VERSION ""

NS_ :

BS_:
BU_: MRR
BO_ 1073741824 VECTOR__INDEPENDENT_SIG_MSG: 0 Vector__XXX
   SG_ New_Signal_943 : 0|8@1+ (1,0) [0|0] "" Vector__XXX
   SG_ CAN_SENSOR_VANGLE_OFFSET : 0|8@0+ (0.0625,-8) [-8|7.9375] "deg" Vector__XXX
   SG_ CAN_SENSOR_FOV_VER : 0|8@0+ (1,0) [0|255] "deg" Vector__XXX
   SG_ CAN_AUTO_ALIGN_VANGLE_QF : 0|1@0+ (1,0) [0|1] "" Vector__XXX
   SG_ CAN_AUTO_ALIGN_VANGLE_REF : 0|10@0+ (0.03125,-10) [-10|21.9688] "deg" Vector__XXX
   SG_ CAN_AUTO_ALIGN_VANGLE : 0|10@0+ (0.03125,-10) [-10|21.9688] "deg" Vector__XXX
   SG_ CAN_MMIC_Temp4 : 0|8@0+ (1,-50) [-50|205] "C" Vector__XXX
   SG_ CAN_MMIC_Temp3 : 0|8@0+ (1,-50) [-50|205] "C" Vector__XXX
   SG_ CAN_MMIC_Temp2 : 0|8@0+ (1,-50) [-50|205] "C" Vector__XXX
   SG_ CAN_Processor_Temp2 : 0|8@0+ (1,-50) [-50|205] "C" Vector__XXX
   SG_ CAN_CHECKSUM : 0|8@0+ (1,0) [0|255] "" Vector__XXX
   SG_ CAN_COUNTER : 0|4@0+ (1,0) [0|15] "" Vector__XXX
   SG_ CAN_VEHICLE_MODE : 0|4@0+ (1,0) [0|15] "" Vector__XXX
   SG_ CAN_USC_CAL_VER_MAJOR : 0|16@0+ (1,0) [0|65535] "" Vector__XXX
   SG_ CAN_USC_CAL_VER_MINOR : 0|16@0+ (1,0) [0|65535] "" Vector__XXX
   SG_ CAN_SMC_CAL_VER_MAJOR : 0|16@0+ (1,0) [0|65535] "" Vector__XXX
   SG_ CAN_HW_VERSION : 0|32@0+ (1,0) [0|4.29497e+09] "" Vector__XXX
   SG_ CAN_FAC_TGT_MTG_SPACE_VER : 0|8@0+ (1,-128) [-128|127] "cm" Vector__XXX
   SG_ CAN_ANGLE_MISALIGNMENT_VER : 0|10@0+ (0.03125,-10) [-10|21.9688] "deg" Vector__XXX
   SG_ CAN_ANGLE_MOUNTING_VOFFSET : 0|8@0+ (0.0625,-8) [-8|7.9375] "deg" Vector__XXX
   SG_ CAN_LATCH_FAULTS : 0|64@0+ (1,0) [0|100] "" Vector__XXX
   SG_ CAN_ACTIVE_FAULTS : 0|64@0+ (1,0) [0|1.84467e+19] "" Vector__XXX
   SG_ CAN_HISTORY_FAULTS : 0|64@0+ (1,0) [0|1.84467e+19] "" Vector__XXX
   SG_ CAN_SERV_ALIGN_ENABLE : 0|1@0+ (1,0) [0|1] "" Vector__XXX
   SG_ CAN_LONG_MOUNTING_OFFSET : 0|8@0+ (0.015625,-2) [-2|1.98438] "" Vector__XXX
   SG_ CAN_BEAMWIDTH_VERT : 0|7@0+ (0.125,0) [0|15.875] "deg" Vector__XXX
   SG_ CAN_VEHICLE_SPEED_CALC_QF : 0|2@0+ (1,0) [0|3] "" Vector__XXX

BO_ 34 Active_Fault_Latched_2: 8 MRR
   SG_ IPMA_PCAN_DataRangeCheck : 4|1@1+ (1,0) [0|1] "" External_Tool
   SG_ IPMA_PCAN_MissingMsg : 3|1@1+ (1,0) [0|1] "" External_Tool
   SG_ VINSignalCompareFailure : 2|1@1+ (1,0) [0|1] "" External_Tool
   SG_ ModuleNotConfiguredError : 1|1@1+ (1,0) [0|1] "" External_Tool
   SG_ CarCfgNotConfiguredError : 0|1@1+ (1,0) [0|1] "" External_Tool

BO_ 33 Active_Fault_Latched_1: 8 MRR
   SG_ Active_Flt_Latched_byte7_bit7 : 63|1@1+ (1,0) [0|1] "" External_Tool
   SG_ Active_Flt_Latched_byte7_bit6 : 62|1@1+ (1,0) [0|1] "" External_Tool
   SG_ Active_Flt_Latched_byte7_bit5 : 61|1@1+ (1,0) [0|1] "" External_Tool
   SG_ Active_Flt_Latched_byte7_bit4 : 60|1@1+ (1,0) [0|1] "" External_Tool
   SG_ ARMtoDSPChksumFault : 59|1@1+ (1,0) [0|1] "" External_Tool
   SG_ DSPtoArmChksumFault : 58|1@1+ (1,0) [0|1] "" External_Tool
   SG_ HostToArmChksumFault : 57|1@1+ (1,0) [0|1] "" External_Tool
   SG_ ARMtoHostChksumFault : 56|1@1+ (1,0) [0|1] "" External_Tool
   SG_ LoopBWOutOfRange : 55|1@1+ (1,0) [0|1] "" External_Tool
   SG_ DSPOverrunFault : 54|1@1+ (1,0) [0|1] "" External_Tool
   SG_ Active_Flt_Latched_byte6_bit5 : 53|1@1+ (1,0) [0|1] "" External_Tool
   SG_ TuningSensitivityFault : 52|1@1+ (1,0) [0|1] "" External_Tool
   SG_ SaturatedTuningFreqFault : 51|1@1+ (1,0) [0|1] "" External_Tool
   SG_ LocalOscPowerFault : 50|1@1+ (1,0) [0|1] "" External_Tool
   SG_ TransmitterPowerFault : 49|1@1+ (1,0) [0|1] "" External_Tool
   SG_ Active_Flt_Latched_byte6_bit0 : 48|1@1+ (1,0) [0|1] "" External_Tool
   SG_ Active_Flt_Latched_byte5_bit7 : 47|1@1+ (1,0) [0|1] "" External_Tool
   SG_ Active_Flt_Latched_byte5_bit6 : 46|1@1+ (1,0) [0|1] "" External_Tool
   SG_ XCVRDeviceSPIFault : 45|1@1+ (1,0) [0|1] "" External_Tool
   SG_ FreqSynthesizerSPIFault : 44|1@1+ (1,0) [0|1] "" External_Tool
   SG_ AnalogConverterDevicSPIFault : 43|1@1+ (1,0) [0|1] "" External_Tool
   SG_ SidelobeBlockage : 42|1@1+ (1,0) [0|1] "" External_Tool
   SG_ Active_Flt_Latched_byte5_bit1 : 41|1@1+ (1,0) [0|1] "" External_Tool
   SG_ MNRBlocked : 40|1@1+ (1,0) [0|1] "" External_Tool
   SG_ ECUTempHighFault : 39|1@1+ (1,0) [0|1] "" External_Tool
   SG_ TransmitterTempHighFault : 38|1@1+ (1,0) [0|1] "" External_Tool
   SG_ AlignmentRoutineFailedFault : 37|1@1+ (1,0) [0|1] "" External_Tool
   SG_ UnreasonableRadarData : 36|1@1+ (1,0) [0|1] "" External_Tool
   SG_ MicroprocessorTempHighFault : 35|1@1+ (1,0) [0|1] "" External_Tool
   SG_ VerticalAlignmentOutOfRange : 34|1@1+ (1,0) [0|1] "" External_Tool
   SG_ HorizontalAlignmentOutOfRange : 33|1@1+ (1,0) [0|1] "" External_Tool
   SG_ FactoryAlignmentMode : 32|1@1+ (1,0) [0|1] "" External_Tool
   SG_ BatteryLowFault : 31|1@1+ (1,0) [0|1] "" External_Tool
   SG_ BatteryHighFault : 30|1@1+ (1,0) [0|1] "" External_Tool
   SG_ v_1p25SupplyOutOfRange : 29|1@1+ (1,0) [0|1] "" External_Tool
   SG_ Active_Flt_Latched_byte3_bit4 : 28|1@1+ (1,0) [0|1] "" External_Tool
   SG_ ThermistorOutOfRange : 27|1@1+ (1,0) [0|1] "" External_Tool
   SG_ v_3p3DACSupplyOutOfRange : 26|1@1+ (1,0) [0|1] "" External_Tool
   SG_ v_3p3RAWSupplyOutOfRange : 25|1@1+ (1,0) [0|1] "" External_Tool
   SG_ v_5_SupplyOutOfRange : 24|1@1+ (1,0) [0|1] "" External_Tool
   SG_ TransmitterIDFault : 23|1@1+ (1,0) [0|1] "" External_Tool
   SG_ Active_Flt_Latched_byte2_bit6 : 22|1@1+ (1,0) [0|1] "" External_Tool
   SG_ Active_Flt_Latched_byte2_bit5 : 21|1@1+ (1,0) [0|1] "" External_Tool
   SG_ Active_Flt_Latched_byte2_bit4 : 20|1@1+ (1,0) [0|1] "" External_Tool
   SG_ Active_Flt_Latched_byte2_bit3 : 19|1@1+ (1,0) [0|1] "" External_Tool
   SG_ Active_Flt_Latched_byte2_bit2 : 18|1@1+ (1,0) [0|1] "" External_Tool
   SG_ PCANMissingMsgFault : 17|1@1+ (1,0) [0|1] "" External_Tool
   SG_ PCANBusOff : 16|1@1+ (1,0) [0|1] "" External_Tool
   SG_ Active_Flt_Latched_byte1_bit7 : 15|1@1+ (1,0) [0|1] "" External_Tool
   SG_ Active_Flt_Latched_byte1_bit6 : 14|1@1+ (1,0) [0|1] "" External_Tool
   SG_ InstructionSetCheckFault : 13|1@1+ (1,0) [0|1] "" External_Tool
   SG_ StackOverflowFault : 12|1@1+ (1,0) [0|1] "" External_Tool
   SG_ WatchdogFault : 11|1@1+ (1,0) [0|1] "" External_Tool
   SG_ PLLLockFault : 10|1@1+ (1,0) [0|1] "" External_Tool
   SG_ Active_Flt_Latched_byte1_bit1 : 9|1@1+ (1,0) [0|1] "" External_Tool
   SG_ RAMMemoryTestFault : 8|1@1+ (1,0) [0|1] "" External_Tool
   SG_ USCValidationFault : 7|1@1+ (1,0) [0|1] "" External_Tool
   SG_ Active_Flt_Latched_byte0_bit6 : 6|1@1+ (1,0) [0|1] "" External_Tool
   SG_ Active_Flt_Latched_byte0_bit5 : 5|1@1+ (1,0) [0|1] "" External_Tool
   SG_ Active_Flt_Latched_byte0_bit4 : 4|1@1+ (1,0) [0|1] "" External_Tool
   SG_ Active_Flt_Latched_byte0_bit3 : 3|1@1+ (1,0) [0|1] "" External_Tool
   SG_ KeepAliveChecksumFault : 2|1@1+ (1,0) [0|1] "" External_Tool
   SG_ ProgramCalibrationFlashChecksum : 1|1@1+ (1,0) [0|1] "" External_Tool
   SG_ ApplicationFlashChecksumFault : 0|1@1+ (1,0) [0|1] "" External_Tool

BO_ 500 XCP_MRR_DAQ_RESP: 8 MRR
   SG_ MRR_xcp_daq_resp_byte7 : 63|8@0+ (1,0) [0|255] "" External_Tool
   SG_ MRR_xcp_daq_resp_byte6 : 55|8@0+ (1,0) [0|255] "" External_Tool
   SG_ MRR_xcp_daq_resp_byte5 : 47|8@0+ (1,0) [0|255] "" External_Tool
   SG_ MRR_xcp_daq_resp_byte4 : 39|8@0+ (1,0) [0|255] "" External_Tool
   SG_ MRR_xcp_daq_resp_byte3 : 31|8@0+ (1,0) [0|255] "" External_Tool
   SG_ MRR_xcp_daq_resp_byte2 : 23|8@0+ (1,0) [0|255] "" External_Tool
   SG_ MRR_xcp_daq_resp_byte1 : 15|8@0+ (1,0) [0|255] "" External_Tool
   SG_ MRR_xcp_daq_resp_byte0 : 7|8@0+ (1,0) [0|255] "" External_Tool

BO_ 499 XCP_MRR_DTO_RESP: 8 MRR
   SG_ MRR_xcp_dto_resp_byte7 : 63|8@0+ (1,0) [0|255] "" External_Tool
   SG_ MRR_xcp_dto_resp_byte6 : 55|8@0+ (1,0) [0|255] "" External_Tool
   SG_ MRR_xcp_dto_resp_byte5 : 47|8@0+ (1,0) [0|255] "" External_Tool
   SG_ MRR_xcp_dto_resp_byte4 : 39|8@0+ (1,0) [0|255] "" External_Tool
   SG_ MRR_xcp_dto_resp_byte3 : 31|8@0+ (1,0) [0|255] "" External_Tool
   SG_ MRR_xcp_dto_resp_byte2 : 23|8@0+ (1,0) [0|255] "" External_Tool
   SG_ MRR_xcp_dto_resp_byte1 : 15|8@0+ (1,0) [0|255] "" External_Tool
   SG_ MRR_xcp_dto_resp_byte0 : 7|8@0+ (1,0) [0|255] "" External_Tool

BO_ 497 XCP_MRR_CTO_RESP: 8 MRR
   SG_ MRR_xcp_cto_resp_byte7 : 63|8@0+ (1,0) [0|255] "" External_Tool
   SG_ MRR_xcp_cto_resp_byte6 : 55|8@0+ (1,0) [0|255] "" External_Tool
   SG_ MRR_xcp_cto_resp_byte5 : 47|8@0+ (1,0) [0|255] "" External_Tool
   SG_ MRR_xcp_cto_resp_byte4 : 39|8@0+ (1,0) [0|255] "" External_Tool
   SG_ MRR_xcp_cto_resp_byte3 : 31|8@0+ (1,0) [0|255] "" External_Tool
   SG_ MRR_xcp_cto_resp_byte2 : 23|8@0+ (1,0) [0|255] "" External_Tool
   SG_ MRR_xcp_cto_resp_byte1 : 15|8@0+ (1,0) [0|255] "" External_Tool
   SG_ MRR_xcp_cto_resp_byte0 : 7|8@0+ (1,0) [0|255] "" External_Tool

BO_ 1900 Ford_Diag_Resp_Phys: 8 MRR
   SG_ TesterPhysicalResCCM : 7|64@0+ (1,0) [0|1.84467e+19] "" IFV_Host

BO_ 261 MRR_Status_SerialNumber: 8 MRR
   SG_ CAN_SEQUENCE_NUMBER : 55|16@0+ (1,0) [0|65535] "" External_Tool
   SG_ CAN_SERIAL_NUMBER : 7|40@0+ (1,0) [0|1.09951e+12] "" External_Tool

BO_ 264 MRR_Status_SwVersion: 8 MRR
   SG_ CAN_PBL_Field_Revision : 47|8@0+ (1,0) [0|255] "" External_Tool
   SG_ CAN_PBL_Promote_Revision : 39|8@0+ (1,0) [0|255] "" External_Tool
   SG_ CAN_SW_Field_Revision : 23|8@0+ (1,0) [0|255] "" External_Tool
   SG_ CAN_SW_Promote_Revision : 15|8@0+ (1,0) [0|255] "" External_Tool
   SG_ CAN_SW_Release_Revision : 7|8@0+ (1,0) [0|255] "" External_Tool
   SG_ CAN_PBL_Release_Revision : 31|8@0+ (1,0) [0|255] "" External_Tool

BO_ 373 MRR_Header_SensorPosition: 8 MRR
   SG_ CAN_SENSOR_POLARITY : 55|1@0+ (1,0) [0|1] "" External_Tool
   SG_ CAN_SENSOR_LAT_OFFSET : 39|16@0+ (0.01,0) [0|655.35] "cm" External_Tool
   SG_ CAN_SENSOR_LONG_OFFSET : 23|16@0+ (0.01,0) [0|655.35] "cm" External_Tool
   SG_ CAN_SENSOR_HANGLE_OFFSET : 7|8@0+ (0.0625,-8) [-8|7.9375] "deg" External_Tool

BO_ 372 MRR_Header_SensorCoverage: 8 MRR
   SG_ CAN_SENSOR_FOV_HOR : 39|8@0+ (1,0) [0|255] "deg" IFV_VFP
   SG_ CAN_DOPPLER_COVERAGE : 23|8@0+ (1,-128) [-128|127] "m/s" IFV_VFP
   SG_ CAN_RANGE_COVERAGE : 7|8@0+ (1,0) [0|255] "m" IFV_VFP

BO_ 371 MRR_Header_AlignmentState: 8 MRR
   SG_ CAN_AUTO_ALIGN_HANGLE_QF : 13|2@0+ (1,0) [0|3] "" IFV_VFP
   SG_ CAN_ALIGNMENT_STATUS : 51|4@0+ (1,0) [0|11] "" IFV_VFP
   SG_ CAN_ALIGNMENT_STATE : 55|3@0+ (1,0) [0|7] "" IFV_VFP
   SG_ CAN_AUTO_ALIGN_HANGLE_REF : 11|10@0+ (0.000341218,-0.174533) [-0.174533|0.174533] "rad" IFV_VFP
   SG_ CAN_AUTO_ALIGN_HANGLE : 7|10@0+ (0.000341218,-0.174533) [-0.174533|0.174533] "rad" IFV_VFP

BO_ 369 MRR_Header_Timestamps: 8 MRR
   SG_ CAN_DET_TIME_SINCE_MEAS : 39|11@0+ (0.1,0) [0|204.7] "ms" IFV_Host
   SG_ CAN_SENSOR_TIME_STAMP : 7|32@0+ (0.1,0) [0|4.29497e+08] "ms" IFV_VFP

BO_ 368 MRR_Header_InformationDetections: 8 MRR
   SG_ CAN_ALIGN_UPDATES_DONE : 55|16@0+ (1,0) [0|65535] "" IFV_VFP
   SG_ CAN_SCAN_INDEX : 31|16@0+ (1,0) [0|65535] "" IFV_VFP
   SG_ CAN_NUMBER_OF_DET : 47|8@0+ (1,0) [0|255] "" External_Tool
   SG_ CAN_LOOK_ID : 23|2@0+ (1,0) [0|3] "" External_Tool
   SG_ CAN_LOOK_INDEX : 7|16@0+ (1,0) [0|65535] "" External_Tool

BO_ 265 MRR_Status_Temp_Volt: 8 MRR
   SG_ CAN_BATT_VOLTS : 63|8@0+ (0.08,0) [0|20.4] "V" External_Tool
   SG_ CAN_1_25_V : 55|8@0+ (0.08,0) [0|20.4] "V" External_Tool
   SG_ CAN_5_V : 47|8@0+ (0.08,0) [0|20.4] "V" External_Tool
   SG_ CAN_3_3_V_RAW : 31|8@0+ (0.08,0) [0|20.4] "V" External_Tool
   SG_ CAN_3_3_V_DAC : 15|8@0+ (0.08,0) [0|20.4] "V" External_Tool
   SG_ CAN_MMIC_Temp1 : 39|8@0+ (1,-50) [-50|205] "C" External_Tool
   SG_ CAN_Processor_Thermistor : 23|8@0+ (1,-50) [-50|205] "C" External_Tool
   SG_ CAN_Processor_Temp1 : 7|8@0+ (1,-50) [-50|205] "C" External_Tool

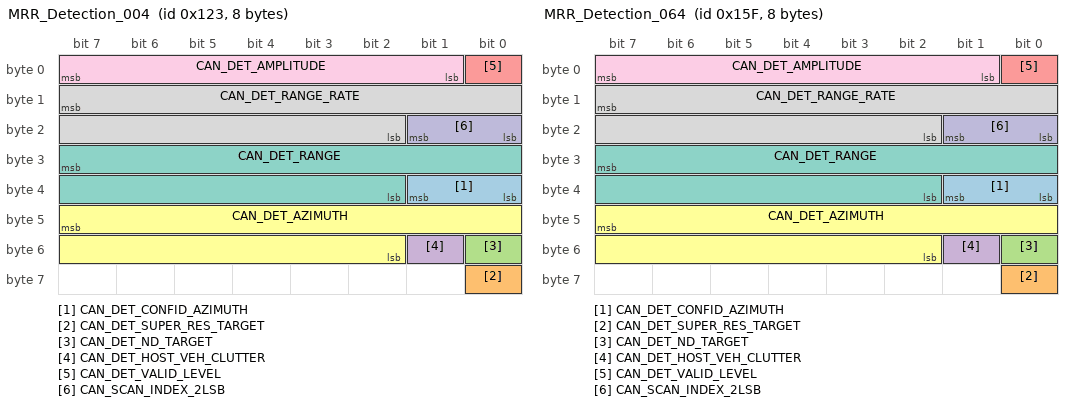
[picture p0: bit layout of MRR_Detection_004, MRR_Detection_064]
BO_ 291 MRR_Detection_004: 8 MRR
   SG_ CAN_DET_CONFID_AZIMUTH : 33|2@0+ (1,0) [0|3] "" IFV_VFP
   SG_ CAN_DET_SUPER_RES_TARGET : 56|1@0+ (1,0) [0|1] "" IFV_VFP
   SG_ CAN_DET_ND_TARGET : 48|1@0+ (1,0) [0|1] "" IFV_VFP
   SG_ CAN_DET_HOST_VEH_CLUTTER : 49|1@0+ (1,0) [0|1] "" IFV_VFP
   SG_ CAN_DET_VALID_LEVEL : 0|1@0+ (1,0) [0|1] "" IFV_VFP
   SG_ CAN_DET_AZIMUTH : 47|14@0+ (0.0003834,-3.1416) [-3.1416|3.13964] "rad" IFV_VFP
   SG_ CAN_DET_RANGE : 31|14@0+ (0.015625,0) [0|255.984] "m" IFV_VFP
   SG_ CAN_DET_RANGE_RATE : 15|14@0+ (0.015625,-128) [-128|127.984] "m/s" IFV_VFP
   SG_ CAN_DET_AMPLITUDE : 7|7@0+ (1,-64) [-64|63] "dBsm" IFV_VFP
   SG_ CAN_SCAN_INDEX_2LSB : 17|2@0+ (1,0) [0|3] "" IFV_VFP

BO_ 351 MRR_Detection_064: 8 MRR
  SG_ CAN_DET_CONFID_AZIMUTH : 33|2@0+ (1,0) [0|3] "" IFV_VFP
  SG_ CAN_DET_SUPER_RES_TARGET : 56|1@0+ (1,0) [0|1] "" IFV_VFP
  SG_ CAN_DET_ND_TARGET : 48|1@0+ (1,0) [0|1] "" IFV_VFP
  SG_ CAN_DET_HOST_VEH_CLUTTER : 49|1@0+ (1,0) [0|1] "" IFV_VFP
  SG_ CAN_DET_VALID_LEVEL : 0|1@0+ (1,0) [0|1] "" IFV_VFP
  SG_ CAN_DET_AZIMUTH : 47|14@0+ (0.0003834,-3.1416) [-3.1416|3.13964] "rad" IFV_VFP
  SG_ CAN_DET_RANGE : 31|14@0+ (0.015625,0) [0|255.984] "m" IFV_VFP
  SG_ CAN_DET_RANGE_RATE : 15|14@0+ (0.015625,-128) [-128|127.984] "m/s" IFV_VFP
  SG_ CAN_DET_AMPLITUDE : 7|7@0+ (1,-64) [-64|63] "dBsm" IFV_VFP
  SG_ CAN_SCAN_INDEX_2LSB : 17|2@0+ (1,0) [0|3] "" IFV_VFP

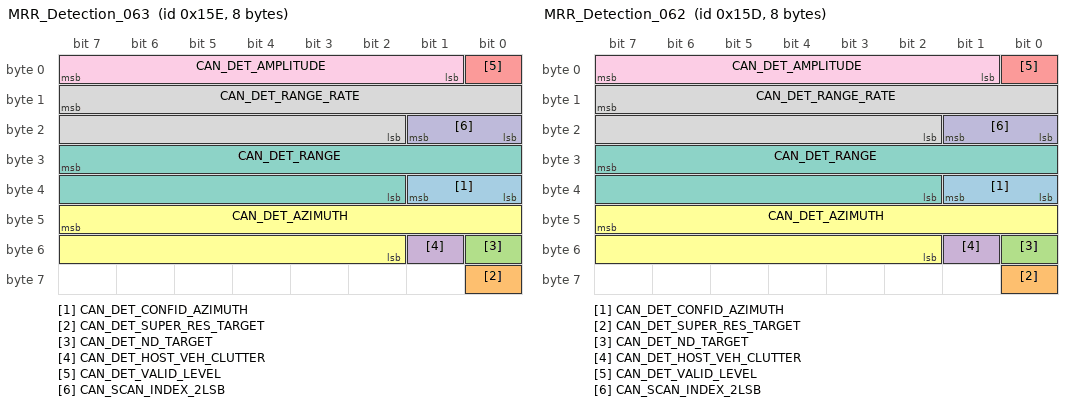
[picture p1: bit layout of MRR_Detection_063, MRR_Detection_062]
BO_ 350 MRR_Detection_063: 8 MRR
  SG_ CAN_DET_CONFID_AZIMUTH : 33|2@0+ (1,0) [0|3] "" IFV_VFP
  SG_ CAN_DET_SUPER_RES_TARGET : 56|1@0+ (1,0) [0|1] "" IFV_VFP
  SG_ CAN_DET_ND_TARGET : 48|1@0+ (1,0) [0|1] "" IFV_VFP
  SG_ CAN_DET_HOST_VEH_CLUTTER : 49|1@0+ (1,0) [0|1] "" IFV_VFP
  SG_ CAN_DET_VALID_LEVEL : 0|1@0+ (1,0) [0|1] "" IFV_VFP
  SG_ CAN_DET_AZIMUTH : 47|14@0+ (0.0003834,-3.1416) [-3.1416|3.13964] "rad" IFV_VFP
  SG_ CAN_DET_RANGE : 31|14@0+ (0.015625,0) [0|255.984] "m" IFV_VFP
  SG_ CAN_DET_RANGE_RATE : 15|14@0+ (0.015625,-128) [-128|127.984] "m/s" IFV_VFP
  SG_ CAN_DET_AMPLITUDE : 7|7@0+ (1,-64) [-64|63] "dBsm" IFV_VFP
  SG_ CAN_SCAN_INDEX_2LSB : 17|2@0+ (1,0) [0|3] "" IFV_VFP

BO_ 349 MRR_Detection_062: 8 MRR
  SG_ CAN_DET_CONFID_AZIMUTH : 33|2@0+ (1,0) [0|3] "" IFV_VFP
  SG_ CAN_DET_SUPER_RES_TARGET : 56|1@0+ (1,0) [0|1] "" IFV_VFP
  SG_ CAN_DET_ND_TARGET : 48|1@0+ (1,0) [0|1] "" IFV_VFP
  SG_ CAN_DET_HOST_VEH_CLUTTER : 49|1@0+ (1,0) [0|1] "" IFV_VFP
  SG_ CAN_DET_VALID_LEVEL : 0|1@0+ (1,0) [0|1] "" IFV_VFP
  SG_ CAN_DET_AZIMUTH : 47|14@0+ (0.0003834,-3.1416) [-3.1416|3.13964] "rad" IFV_VFP
  SG_ CAN_DET_RANGE : 31|14@0+ (0.015625,0) [0|255.984] "m" IFV_VFP
  SG_ CAN_DET_RANGE_RATE : 15|14@0+ (0.015625,-128) [-128|127.984] "m/s" IFV_VFP
  SG_ CAN_DET_AMPLITUDE : 7|7@0+ (1,-64) [-64|63] "dBsm" IFV_VFP
  SG_ CAN_SCAN_INDEX_2LSB : 17|2@0+ (1,0) [0|3] "" IFV_VFP

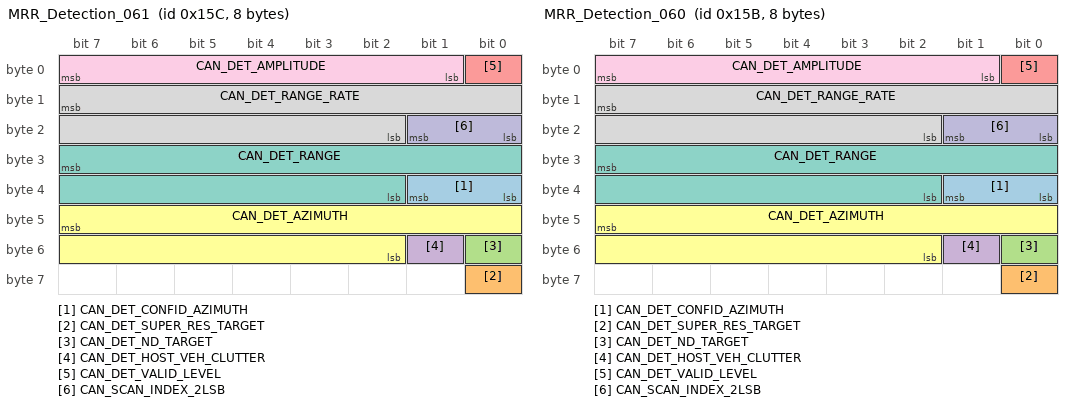
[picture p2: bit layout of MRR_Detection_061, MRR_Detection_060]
BO_ 348 MRR_Detection_061: 8 MRR
  SG_ CAN_DET_CONFID_AZIMUTH : 33|2@0+ (1,0) [0|3] "" IFV_VFP
  SG_ CAN_DET_SUPER_RES_TARGET : 56|1@0+ (1,0) [0|1] "" IFV_VFP
  SG_ CAN_DET_ND_TARGET : 48|1@0+ (1,0) [0|1] "" IFV_VFP
  SG_ CAN_DET_HOST_VEH_CLUTTER : 49|1@0+ (1,0) [0|1] "" IFV_VFP
  SG_ CAN_DET_VALID_LEVEL : 0|1@0+ (1,0) [0|1] "" IFV_VFP
  SG_ CAN_DET_AZIMUTH : 47|14@0+ (0.0003834,-3.1416) [-3.1416|3.13964] "rad" IFV_VFP
  SG_ CAN_DET_RANGE : 31|14@0+ (0.015625,0) [0|255.984] "m" IFV_VFP
  SG_ CAN_DET_RANGE_RATE : 15|14@0+ (0.015625,-128) [-128|127.984] "m/s" IFV_VFP
  SG_ CAN_DET_AMPLITUDE : 7|7@0+ (1,-64) [-64|63] "dBsm" IFV_VFP
  SG_ CAN_SCAN_INDEX_2LSB : 17|2@0+ (1,0) [0|3] "" IFV_VFP

BO_ 347 MRR_Detection_060: 8 MRR
  SG_ CAN_DET_CONFID_AZIMUTH : 33|2@0+ (1,0) [0|3] "" IFV_VFP
  SG_ CAN_DET_SUPER_RES_TARGET : 56|1@0+ (1,0) [0|1] "" IFV_VFP
  SG_ CAN_DET_ND_TARGET : 48|1@0+ (1,0) [0|1] "" IFV_VFP
  SG_ CAN_DET_HOST_VEH_CLUTTER : 49|1@0+ (1,0) [0|1] "" IFV_VFP
  SG_ CAN_DET_VALID_LEVEL : 0|1@0+ (1,0) [0|1] "" IFV_VFP
  SG_ CAN_DET_AZIMUTH : 47|14@0+ (0.0003834,-3.1416) [-3.1416|3.13964] "rad" IFV_VFP
  SG_ CAN_DET_RANGE : 31|14@0+ (0.015625,0) [0|255.984] "m" IFV_VFP
  SG_ CAN_DET_RANGE_RATE : 15|14@0+ (0.015625,-128) [-128|127.984] "m/s" IFV_VFP
  SG_ CAN_DET_AMPLITUDE : 7|7@0+ (1,-64) [-64|63] "dBsm" IFV_VFP
  SG_ CAN_SCAN_INDEX_2LSB : 17|2@0+ (1,0) [0|3] "" IFV_VFP

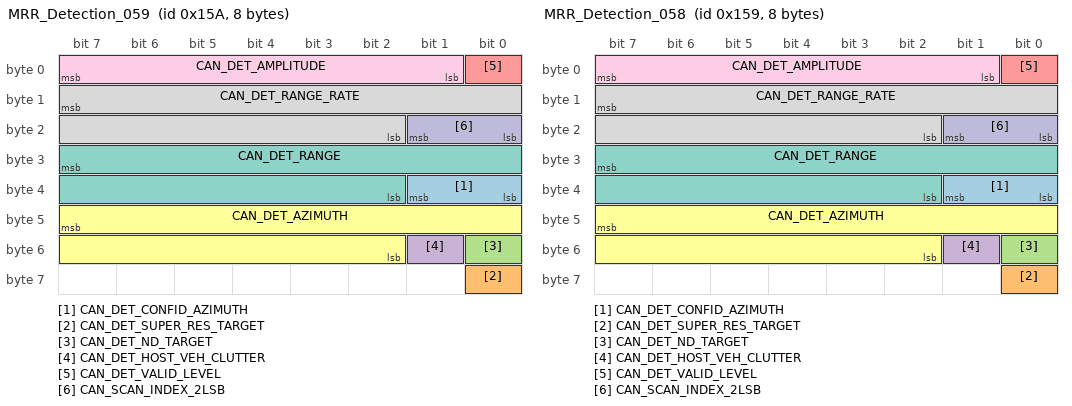
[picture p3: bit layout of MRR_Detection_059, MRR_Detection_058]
BO_ 346 MRR_Detection_059: 8 MRR
  SG_ CAN_DET_CONFID_AZIMUTH : 33|2@0+ (1,0) [0|3] "" IFV_VFP
  SG_ CAN_DET_SUPER_RES_TARGET : 56|1@0+ (1,0) [0|1] "" IFV_VFP
  SG_ CAN_DET_ND_TARGET : 48|1@0+ (1,0) [0|1] "" IFV_VFP
  SG_ CAN_DET_HOST_VEH_CLUTTER : 49|1@0+ (1,0) [0|1] "" IFV_VFP
  SG_ CAN_DET_VALID_LEVEL : 0|1@0+ (1,0) [0|1] "" IFV_VFP
  SG_ CAN_DET_AZIMUTH : 47|14@0+ (0.0003834,-3.1416) [-3.1416|3.13964] "rad" IFV_VFP
  SG_ CAN_DET_RANGE : 31|14@0+ (0.015625,0) [0|255.984] "m" IFV_VFP
  SG_ CAN_DET_RANGE_RATE : 15|14@0+ (0.015625,-128) [-128|127.984] "m/s" IFV_VFP
  SG_ CAN_DET_AMPLITUDE : 7|7@0+ (1,-64) [-64|63] "dBsm" IFV_VFP
  SG_ CAN_SCAN_INDEX_2LSB : 17|2@0+ (1,0) [0|3] "" IFV_VFP

BO_ 345 MRR_Detection_058: 8 MRR
  SG_ CAN_DET_CONFID_AZIMUTH : 33|2@0+ (1,0) [0|3] "" IFV_VFP
  SG_ CAN_DET_SUPER_RES_TARGET : 56|1@0+ (1,0) [0|1] "" IFV_VFP
  SG_ CAN_DET_ND_TARGET : 48|1@0+ (1,0) [0|1] "" IFV_VFP
  SG_ CAN_DET_HOST_VEH_CLUTTER : 49|1@0+ (1,0) [0|1] "" IFV_VFP
  SG_ CAN_DET_VALID_LEVEL : 0|1@0+ (1,0) [0|1] "" IFV_VFP
  SG_ CAN_DET_AZIMUTH : 47|14@0+ (0.0003834,-3.1416) [-3.1416|3.13964] "rad" IFV_VFP
  SG_ CAN_DET_RANGE : 31|14@0+ (0.015625,0) [0|255.984] "m" IFV_VFP
  SG_ CAN_DET_RANGE_RATE : 15|14@0+ (0.015625,-128) [-128|127.984] "m/s" IFV_VFP
  SG_ CAN_DET_AMPLITUDE : 7|7@0+ (1,-64) [-64|63] "dBsm" IFV_VFP
  SG_ CAN_SCAN_INDEX_2LSB : 17|2@0+ (1,0) [0|3] "" IFV_VFP

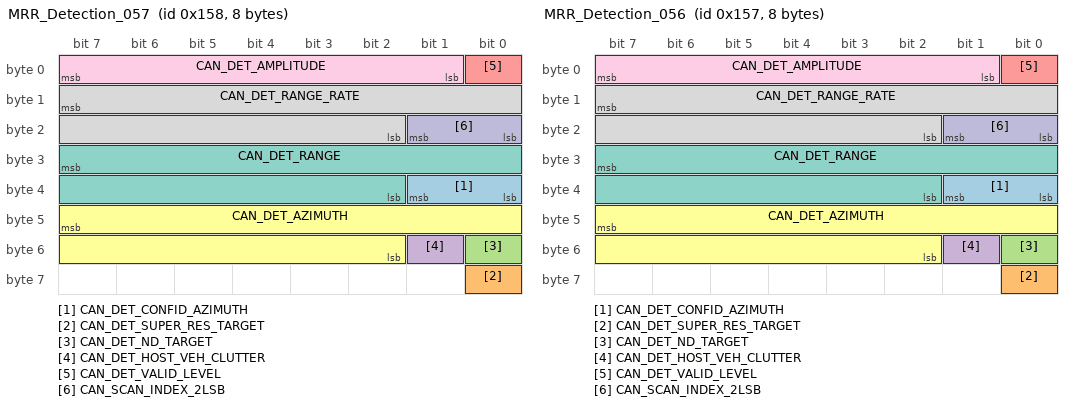
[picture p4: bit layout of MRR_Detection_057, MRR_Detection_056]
BO_ 344 MRR_Detection_057: 8 MRR
  SG_ CAN_DET_CONFID_AZIMUTH : 33|2@0+ (1,0) [0|3] "" IFV_VFP
  SG_ CAN_DET_SUPER_RES_TARGET : 56|1@0+ (1,0) [0|1] "" IFV_VFP
  SG_ CAN_DET_ND_TARGET : 48|1@0+ (1,0) [0|1] "" IFV_VFP
  SG_ CAN_DET_HOST_VEH_CLUTTER : 49|1@0+ (1,0) [0|1] "" IFV_VFP
  SG_ CAN_DET_VALID_LEVEL : 0|1@0+ (1,0) [0|1] "" IFV_VFP
  SG_ CAN_DET_AZIMUTH : 47|14@0+ (0.0003834,-3.1416) [-3.1416|3.13964] "rad" IFV_VFP
  SG_ CAN_DET_RANGE : 31|14@0+ (0.015625,0) [0|255.984] "m" IFV_VFP
  SG_ CAN_DET_RANGE_RATE : 15|14@0+ (0.015625,-128) [-128|127.984] "m/s" IFV_VFP
  SG_ CAN_DET_AMPLITUDE : 7|7@0+ (1,-64) [-64|63] "dBsm" IFV_VFP
  SG_ CAN_SCAN_INDEX_2LSB : 17|2@0+ (1,0) [0|3] "" IFV_VFP

BO_ 343 MRR_Detection_056: 8 MRR
  SG_ CAN_DET_CONFID_AZIMUTH : 33|2@0+ (1,0) [0|3] "" IFV_VFP
  SG_ CAN_DET_SUPER_RES_TARGET : 56|1@0+ (1,0) [0|1] "" IFV_VFP
  SG_ CAN_DET_ND_TARGET : 48|1@0+ (1,0) [0|1] "" IFV_VFP
  SG_ CAN_DET_HOST_VEH_CLUTTER : 49|1@0+ (1,0) [0|1] "" IFV_VFP
  SG_ CAN_DET_VALID_LEVEL : 0|1@0+ (1,0) [0|1] "" IFV_VFP
  SG_ CAN_DET_AZIMUTH : 47|14@0+ (0.0003834,-3.1416) [-3.1416|3.13964] "rad" IFV_VFP
  SG_ CAN_DET_RANGE : 31|14@0+ (0.015625,0) [0|255.984] "m" IFV_VFP
  SG_ CAN_DET_RANGE_RATE : 15|14@0+ (0.015625,-128) [-128|127.984] "m/s" IFV_VFP
  SG_ CAN_DET_AMPLITUDE : 7|7@0+ (1,-64) [-64|63] "dBsm" IFV_VFP
  SG_ CAN_SCAN_INDEX_2LSB : 17|2@0+ (1,0) [0|3] "" IFV_VFP

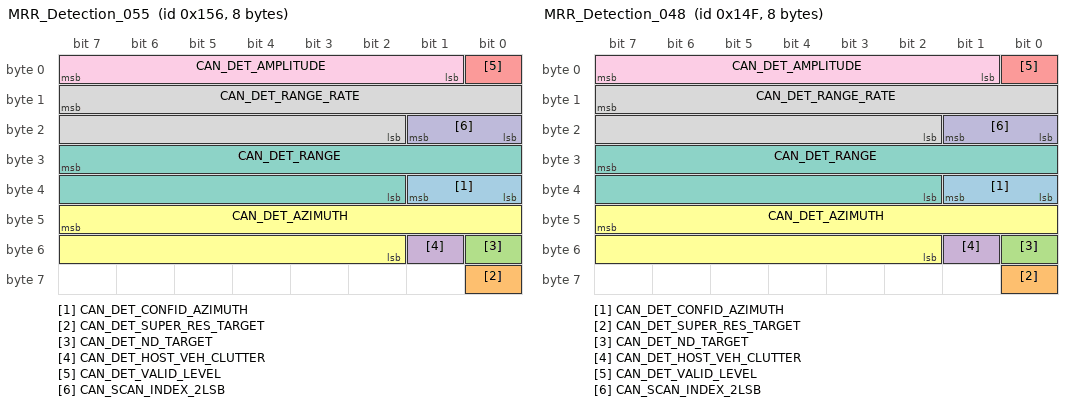
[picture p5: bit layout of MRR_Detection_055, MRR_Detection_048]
BO_ 342 MRR_Detection_055: 8 MRR
  SG_ CAN_DET_CONFID_AZIMUTH : 33|2@0+ (1,0) [0|3] "" IFV_VFP
  SG_ CAN_DET_SUPER_RES_TARGET : 56|1@0+ (1,0) [0|1] "" IFV_VFP
  SG_ CAN_DET_ND_TARGET : 48|1@0+ (1,0) [0|1] "" IFV_VFP
  SG_ CAN_DET_HOST_VEH_CLUTTER : 49|1@0+ (1,0) [0|1] "" IFV_VFP
  SG_ CAN_DET_VALID_LEVEL : 0|1@0+ (1,0) [0|1] "" IFV_VFP
  SG_ CAN_DET_AZIMUTH : 47|14@0+ (0.0003834,-3.1416) [-3.1416|3.13964] "rad" IFV_VFP
  SG_ CAN_DET_RANGE : 31|14@0+ (0.015625,0) [0|255.984] "m" IFV_VFP
  SG_ CAN_DET_RANGE_RATE : 15|14@0+ (0.015625,-128) [-128|127.984] "m/s" IFV_VFP
  SG_ CAN_DET_AMPLITUDE : 7|7@0+ (1,-64) [-64|63] "dBsm" IFV_VFP
  SG_ CAN_SCAN_INDEX_2LSB : 17|2@0+ (1,0) [0|3] "" IFV_VFP

BO_ 335 MRR_Detection_048: 8 MRR
  SG_ CAN_DET_CONFID_AZIMUTH : 33|2@0+ (1,0) [0|3] "" IFV_VFP
  SG_ CAN_DET_SUPER_RES_TARGET : 56|1@0+ (1,0) [0|1] "" IFV_VFP
  SG_ CAN_DET_ND_TARGET : 48|1@0+ (1,0) [0|1] "" IFV_VFP
  SG_ CAN_DET_HOST_VEH_CLUTTER : 49|1@0+ (1,0) [0|1] "" IFV_VFP
  SG_ CAN_DET_VALID_LEVEL : 0|1@0+ (1,0) [0|1] "" IFV_VFP
  SG_ CAN_DET_AZIMUTH : 47|14@0+ (0.0003834,-3.1416) [-3.1416|3.13964] "rad" IFV_VFP
  SG_ CAN_DET_RANGE : 31|14@0+ (0.015625,0) [0|255.984] "m" IFV_VFP
  SG_ CAN_DET_RANGE_RATE : 15|14@0+ (0.015625,-128) [-128|127.984] "m/s" IFV_VFP
  SG_ CAN_DET_AMPLITUDE : 7|7@0+ (1,-64) [-64|63] "dBsm" IFV_VFP
  SG_ CAN_SCAN_INDEX_2LSB : 17|2@0+ (1,0) [0|3] "" IFV_VFP

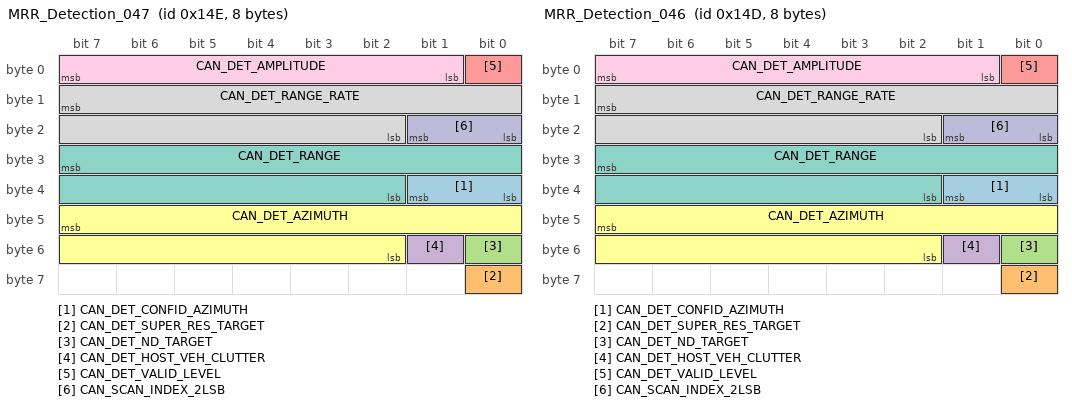
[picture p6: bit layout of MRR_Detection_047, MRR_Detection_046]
BO_ 334 MRR_Detection_047: 8 MRR
  SG_ CAN_DET_CONFID_AZIMUTH : 33|2@0+ (1,0) [0|3] "" IFV_VFP
  SG_ CAN_DET_SUPER_RES_TARGET : 56|1@0+ (1,0) [0|1] "" IFV_VFP
  SG_ CAN_DET_ND_TARGET : 48|1@0+ (1,0) [0|1] "" IFV_VFP
  SG_ CAN_DET_HOST_VEH_CLUTTER : 49|1@0+ (1,0) [0|1] "" IFV_VFP
  SG_ CAN_DET_VALID_LEVEL : 0|1@0+ (1,0) [0|1] "" IFV_VFP
  SG_ CAN_DET_AZIMUTH : 47|14@0+ (0.0003834,-3.1416) [-3.1416|3.13964] "rad" IFV_VFP
  SG_ CAN_DET_RANGE : 31|14@0+ (0.015625,0) [0|255.984] "m" IFV_VFP
  SG_ CAN_DET_RANGE_RATE : 15|14@0+ (0.015625,-128) [-128|127.984] "m/s" IFV_VFP
  SG_ CAN_DET_AMPLITUDE : 7|7@0+ (1,-64) [-64|63] "dBsm" IFV_VFP
  SG_ CAN_SCAN_INDEX_2LSB : 17|2@0+ (1,0) [0|3] "" IFV_VFP

BO_ 333 MRR_Detection_046: 8 MRR
  SG_ CAN_DET_CONFID_AZIMUTH : 33|2@0+ (1,0) [0|3] "" IFV_VFP
  SG_ CAN_DET_SUPER_RES_TARGET : 56|1@0+ (1,0) [0|1] "" IFV_VFP
  SG_ CAN_DET_ND_TARGET : 48|1@0+ (1,0) [0|1] "" IFV_VFP
  SG_ CAN_DET_HOST_VEH_CLUTTER : 49|1@0+ (1,0) [0|1] "" IFV_VFP
  SG_ CAN_DET_VALID_LEVEL : 0|1@0+ (1,0) [0|1] "" IFV_VFP
  SG_ CAN_DET_AZIMUTH : 47|14@0+ (0.0003834,-3.1416) [-3.1416|3.13964] "rad" IFV_VFP
  SG_ CAN_DET_RANGE : 31|14@0+ (0.015625,0) [0|255.984] "m" IFV_VFP
  SG_ CAN_DET_RANGE_RATE : 15|14@0+ (0.015625,-128) [-128|127.984] "m/s" IFV_VFP
  SG_ CAN_DET_AMPLITUDE : 7|7@0+ (1,-64) [-64|63] "dBsm" IFV_VFP
  SG_ CAN_SCAN_INDEX_2LSB : 17|2@0+ (1,0) [0|3] "" IFV_VFP

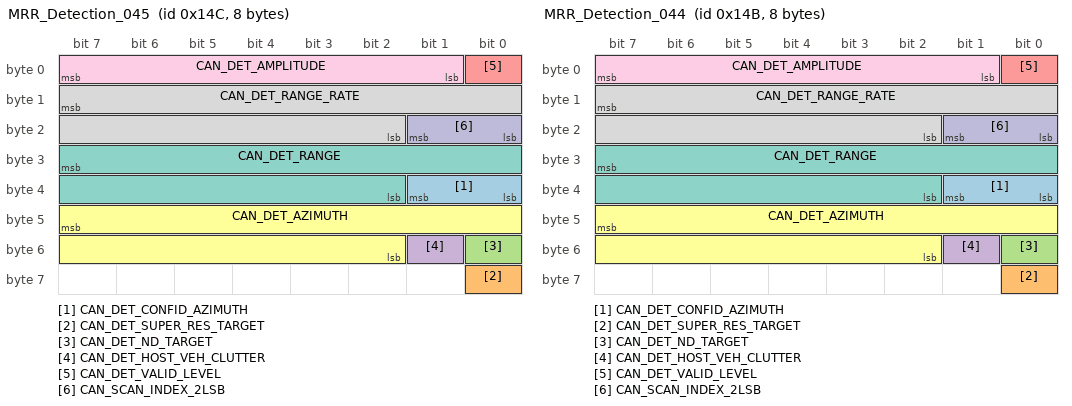
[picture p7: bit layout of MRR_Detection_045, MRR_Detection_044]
BO_ 332 MRR_Detection_045: 8 MRR
  SG_ CAN_DET_CONFID_AZIMUTH : 33|2@0+ (1,0) [0|3] "" IFV_VFP
  SG_ CAN_DET_SUPER_RES_TARGET : 56|1@0+ (1,0) [0|1] "" IFV_VFP
  SG_ CAN_DET_ND_TARGET : 48|1@0+ (1,0) [0|1] "" IFV_VFP
  SG_ CAN_DET_HOST_VEH_CLUTTER : 49|1@0+ (1,0) [0|1] "" IFV_VFP
  SG_ CAN_DET_VALID_LEVEL : 0|1@0+ (1,0) [0|1] "" IFV_VFP
  SG_ CAN_DET_AZIMUTH : 47|14@0+ (0.0003834,-3.1416) [-3.1416|3.13964] "rad" IFV_VFP
  SG_ CAN_DET_RANGE : 31|14@0+ (0.015625,0) [0|255.984] "m" IFV_VFP
  SG_ CAN_DET_RANGE_RATE : 15|14@0+ (0.015625,-128) [-128|127.984] "m/s" IFV_VFP
  SG_ CAN_DET_AMPLITUDE : 7|7@0+ (1,-64) [-64|63] "dBsm" IFV_VFP
  SG_ CAN_SCAN_INDEX_2LSB : 17|2@0+ (1,0) [0|3] "" IFV_VFP

BO_ 331 MRR_Detection_044: 8 MRR
  SG_ CAN_DET_CONFID_AZIMUTH : 33|2@0+ (1,0) [0|3] "" IFV_VFP
  SG_ CAN_DET_SUPER_RES_TARGET : 56|1@0+ (1,0) [0|1] "" IFV_VFP
  SG_ CAN_DET_ND_TARGET : 48|1@0+ (1,0) [0|1] "" IFV_VFP
  SG_ CAN_DET_HOST_VEH_CLUTTER : 49|1@0+ (1,0) [0|1] "" IFV_VFP
  SG_ CAN_DET_VALID_LEVEL : 0|1@0+ (1,0) [0|1] "" IFV_VFP
  SG_ CAN_DET_AZIMUTH : 47|14@0+ (0.0003834,-3.1416) [-3.1416|3.13964] "rad" IFV_VFP
  SG_ CAN_DET_RANGE : 31|14@0+ (0.015625,0) [0|255.984] "m" IFV_VFP
  SG_ CAN_DET_RANGE_RATE : 15|14@0+ (0.015625,-128) [-128|127.984] "m/s" IFV_VFP
  SG_ CAN_DET_AMPLITUDE : 7|7@0+ (1,-64) [-64|63] "dBsm" IFV_VFP
  SG_ CAN_SCAN_INDEX_2LSB : 17|2@0+ (1,0) [0|3] "" IFV_VFP

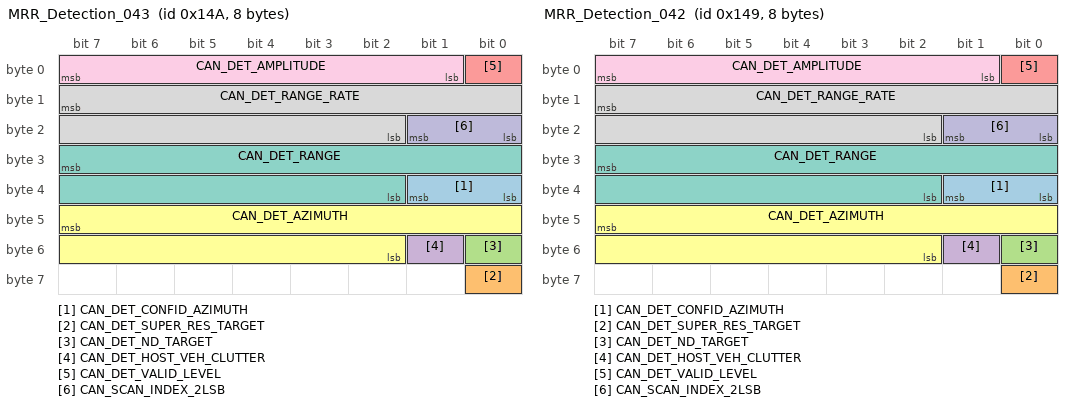
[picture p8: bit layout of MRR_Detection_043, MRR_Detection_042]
BO_ 330 MRR_Detection_043: 8 MRR
  SG_ CAN_DET_CONFID_AZIMUTH : 33|2@0+ (1,0) [0|3] "" IFV_VFP
  SG_ CAN_DET_SUPER_RES_TARGET : 56|1@0+ (1,0) [0|1] "" IFV_VFP
  SG_ CAN_DET_ND_TARGET : 48|1@0+ (1,0) [0|1] "" IFV_VFP
  SG_ CAN_DET_HOST_VEH_CLUTTER : 49|1@0+ (1,0) [0|1] "" IFV_VFP
  SG_ CAN_DET_VALID_LEVEL : 0|1@0+ (1,0) [0|1] "" IFV_VFP
  SG_ CAN_DET_AZIMUTH : 47|14@0+ (0.0003834,-3.1416) [-3.1416|3.13964] "rad" IFV_VFP
  SG_ CAN_DET_RANGE : 31|14@0+ (0.015625,0) [0|255.984] "m" IFV_VFP
  SG_ CAN_DET_RANGE_RATE : 15|14@0+ (0.015625,-128) [-128|127.984] "m/s" IFV_VFP
  SG_ CAN_DET_AMPLITUDE : 7|7@0+ (1,-64) [-64|63] "dBsm" IFV_VFP
  SG_ CAN_SCAN_INDEX_2LSB : 17|2@0+ (1,0) [0|3] "" IFV_VFP

BO_ 329 MRR_Detection_042: 8 MRR
  SG_ CAN_DET_CONFID_AZIMUTH : 33|2@0+ (1,0) [0|3] "" IFV_VFP
  SG_ CAN_DET_SUPER_RES_TARGET : 56|1@0+ (1,0) [0|1] "" IFV_VFP
  SG_ CAN_DET_ND_TARGET : 48|1@0+ (1,0) [0|1] "" IFV_VFP
  SG_ CAN_DET_HOST_VEH_CLUTTER : 49|1@0+ (1,0) [0|1] "" IFV_VFP
  SG_ CAN_DET_VALID_LEVEL : 0|1@0+ (1,0) [0|1] "" IFV_VFP
  SG_ CAN_DET_AZIMUTH : 47|14@0+ (0.0003834,-3.1416) [-3.1416|3.13964] "rad" IFV_VFP
  SG_ CAN_DET_RANGE : 31|14@0+ (0.015625,0) [0|255.984] "m" IFV_VFP
  SG_ CAN_DET_RANGE_RATE : 15|14@0+ (0.015625,-128) [-128|127.984] "m/s" IFV_VFP
  SG_ CAN_DET_AMPLITUDE : 7|7@0+ (1,-64) [-64|63] "dBsm" IFV_VFP
  SG_ CAN_SCAN_INDEX_2LSB : 17|2@0+ (1,0) [0|3] "" IFV_VFP

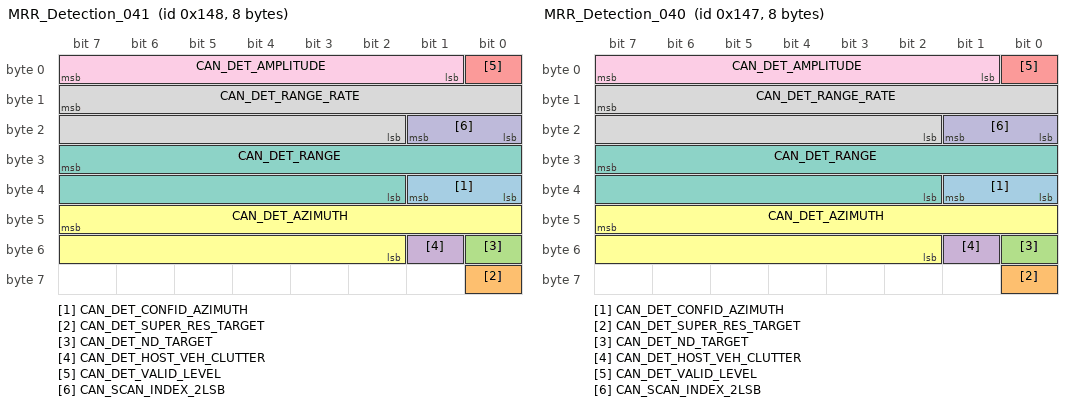
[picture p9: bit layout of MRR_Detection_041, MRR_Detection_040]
BO_ 328 MRR_Detection_041: 8 MRR
  SG_ CAN_DET_CONFID_AZIMUTH : 33|2@0+ (1,0) [0|3] "" IFV_VFP
  SG_ CAN_DET_SUPER_RES_TARGET : 56|1@0+ (1,0) [0|1] "" IFV_VFP
  SG_ CAN_DET_ND_TARGET : 48|1@0+ (1,0) [0|1] "" IFV_VFP
  SG_ CAN_DET_HOST_VEH_CLUTTER : 49|1@0+ (1,0) [0|1] "" IFV_VFP
  SG_ CAN_DET_VALID_LEVEL : 0|1@0+ (1,0) [0|1] "" IFV_VFP
  SG_ CAN_DET_AZIMUTH : 47|14@0+ (0.0003834,-3.1416) [-3.1416|3.13964] "rad" IFV_VFP
  SG_ CAN_DET_RANGE : 31|14@0+ (0.015625,0) [0|255.984] "m" IFV_VFP
  SG_ CAN_DET_RANGE_RATE : 15|14@0+ (0.015625,-128) [-128|127.984] "m/s" IFV_VFP
  SG_ CAN_DET_AMPLITUDE : 7|7@0+ (1,-64) [-64|63] "dBsm" IFV_VFP
  SG_ CAN_SCAN_INDEX_2LSB : 17|2@0+ (1,0) [0|3] "" IFV_VFP

BO_ 327 MRR_Detection_040: 8 MRR
  SG_ CAN_DET_CONFID_AZIMUTH : 33|2@0+ (1,0) [0|3] "" IFV_VFP
  SG_ CAN_DET_SUPER_RES_TARGET : 56|1@0+ (1,0) [0|1] "" IFV_VFP
  SG_ CAN_DET_ND_TARGET : 48|1@0+ (1,0) [0|1] "" IFV_VFP
  SG_ CAN_DET_HOST_VEH_CLUTTER : 49|1@0+ (1,0) [0|1] "" IFV_VFP
  SG_ CAN_DET_VALID_LEVEL : 0|1@0+ (1,0) [0|1] "" IFV_VFP
  SG_ CAN_DET_AZIMUTH : 47|14@0+ (0.0003834,-3.1416) [-3.1416|3.13964] "rad" IFV_VFP
  SG_ CAN_DET_RANGE : 31|14@0+ (0.015625,0) [0|255.984] "m" IFV_VFP
  SG_ CAN_DET_RANGE_RATE : 15|14@0+ (0.015625,-128) [-128|127.984] "m/s" IFV_VFP
  SG_ CAN_DET_AMPLITUDE : 7|7@0+ (1,-64) [-64|63] "dBsm" IFV_VFP
  SG_ CAN_SCAN_INDEX_2LSB : 17|2@0+ (1,0) [0|3] "" IFV_VFP

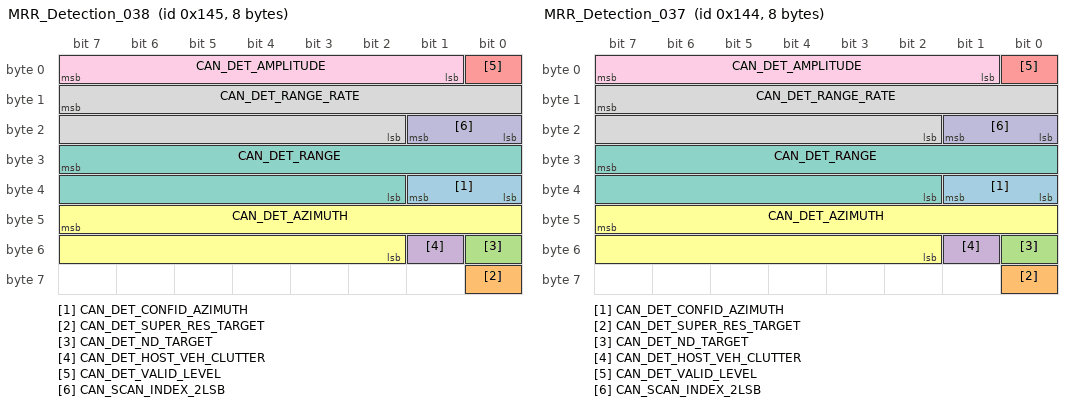
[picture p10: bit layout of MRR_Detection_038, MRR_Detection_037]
BO_ 325 MRR_Detection_038: 8 MRR
  SG_ CAN_DET_CONFID_AZIMUTH : 33|2@0+ (1,0) [0|3] "" IFV_VFP
  SG_ CAN_DET_SUPER_RES_TARGET : 56|1@0+ (1,0) [0|1] "" IFV_VFP
  SG_ CAN_DET_ND_TARGET : 48|1@0+ (1,0) [0|1] "" IFV_VFP
  SG_ CAN_DET_HOST_VEH_CLUTTER : 49|1@0+ (1,0) [0|1] "" IFV_VFP
  SG_ CAN_DET_VALID_LEVEL : 0|1@0+ (1,0) [0|1] "" IFV_VFP
  SG_ CAN_DET_AZIMUTH : 47|14@0+ (0.0003834,-3.1416) [-3.1416|3.13964] "rad" IFV_VFP
  SG_ CAN_DET_RANGE : 31|14@0+ (0.015625,0) [0|255.984] "m" IFV_VFP
  SG_ CAN_DET_RANGE_RATE : 15|14@0+ (0.015625,-128) [-128|127.984] "m/s" IFV_VFP
  SG_ CAN_DET_AMPLITUDE : 7|7@0+ (1,-64) [-64|63] "dBsm" IFV_VFP
  SG_ CAN_SCAN_INDEX_2LSB : 17|2@0+ (1,0) [0|3] "" IFV_VFP

BO_ 324 MRR_Detection_037: 8 MRR
  SG_ CAN_DET_CONFID_AZIMUTH : 33|2@0+ (1,0) [0|3] "" IFV_VFP
  SG_ CAN_DET_SUPER_RES_TARGET : 56|1@0+ (1,0) [0|1] "" IFV_VFP
  SG_ CAN_DET_ND_TARGET : 48|1@0+ (1,0) [0|1] "" IFV_VFP
  SG_ CAN_DET_HOST_VEH_CLUTTER : 49|1@0+ (1,0) [0|1] "" IFV_VFP
  SG_ CAN_DET_VALID_LEVEL : 0|1@0+ (1,0) [0|1] "" IFV_VFP
  SG_ CAN_DET_AZIMUTH : 47|14@0+ (0.0003834,-3.1416) [-3.1416|3.13964] "rad" IFV_VFP
  SG_ CAN_DET_RANGE : 31|14@0+ (0.015625,0) [0|255.984] "m" IFV_VFP
  SG_ CAN_DET_RANGE_RATE : 15|14@0+ (0.015625,-128) [-128|127.984] "m/s" IFV_VFP
  SG_ CAN_DET_AMPLITUDE : 7|7@0+ (1,-64) [-64|63] "dBsm" IFV_VFP
  SG_ CAN_SCAN_INDEX_2LSB : 17|2@0+ (1,0) [0|3] "" IFV_VFP

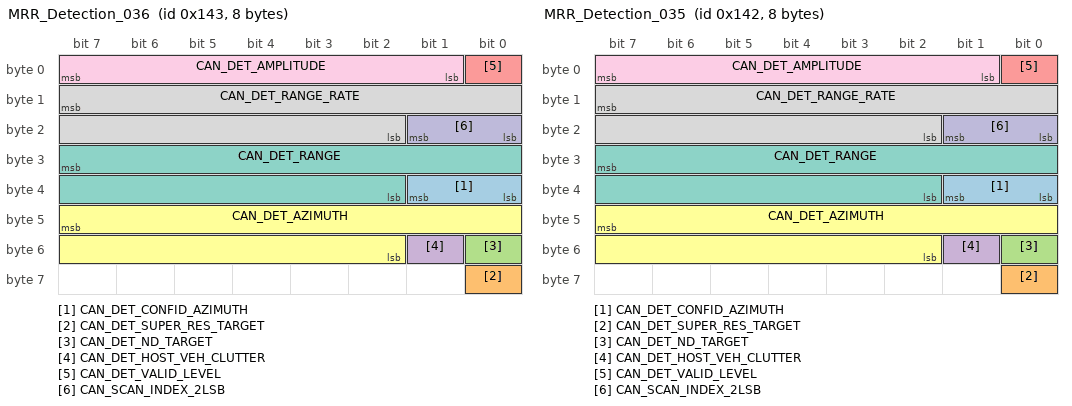
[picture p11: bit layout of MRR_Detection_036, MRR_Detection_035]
BO_ 323 MRR_Detection_036: 8 MRR
  SG_ CAN_DET_CONFID_AZIMUTH : 33|2@0+ (1,0) [0|3] "" IFV_VFP
  SG_ CAN_DET_SUPER_RES_TARGET : 56|1@0+ (1,0) [0|1] "" IFV_VFP
  SG_ CAN_DET_ND_TARGET : 48|1@0+ (1,0) [0|1] "" IFV_VFP
  SG_ CAN_DET_HOST_VEH_CLUTTER : 49|1@0+ (1,0) [0|1] "" IFV_VFP
  SG_ CAN_DET_VALID_LEVEL : 0|1@0+ (1,0) [0|1] "" IFV_VFP
  SG_ CAN_DET_AZIMUTH : 47|14@0+ (0.0003834,-3.1416) [-3.1416|3.13964] "rad" IFV_VFP
  SG_ CAN_DET_RANGE : 31|14@0+ (0.015625,0) [0|255.984] "m" IFV_VFP
  SG_ CAN_DET_RANGE_RATE : 15|14@0+ (0.015625,-128) [-128|127.984] "m/s" IFV_VFP
  SG_ CAN_DET_AMPLITUDE : 7|7@0+ (1,-64) [-64|63] "dBsm" IFV_VFP
  SG_ CAN_SCAN_INDEX_2LSB : 17|2@0+ (1,0) [0|3] "" IFV_VFP

BO_ 322 MRR_Detection_035: 8 MRR
  SG_ CAN_DET_CONFID_AZIMUTH : 33|2@0+ (1,0) [0|3] "" IFV_VFP
  SG_ CAN_DET_SUPER_RES_TARGET : 56|1@0+ (1,0) [0|1] "" IFV_VFP
  SG_ CAN_DET_ND_TARGET : 48|1@0+ (1,0) [0|1] "" IFV_VFP
  SG_ CAN_DET_HOST_VEH_CLUTTER : 49|1@0+ (1,0) [0|1] "" IFV_VFP
  SG_ CAN_DET_VALID_LEVEL : 0|1@0+ (1,0) [0|1] "" IFV_VFP
  SG_ CAN_DET_AZIMUTH : 47|14@0+ (0.0003834,-3.1416) [-3.1416|3.13964] "rad" IFV_VFP
  SG_ CAN_DET_RANGE : 31|14@0+ (0.015625,0) [0|255.984] "m" IFV_VFP
  SG_ CAN_DET_RANGE_RATE : 15|14@0+ (0.015625,-128) [-128|127.984] "m/s" IFV_VFP
  SG_ CAN_DET_AMPLITUDE : 7|7@0+ (1,-64) [-64|63] "dBsm" IFV_VFP
  SG_ CAN_SCAN_INDEX_2LSB : 17|2@0+ (1,0) [0|3] "" IFV_VFP

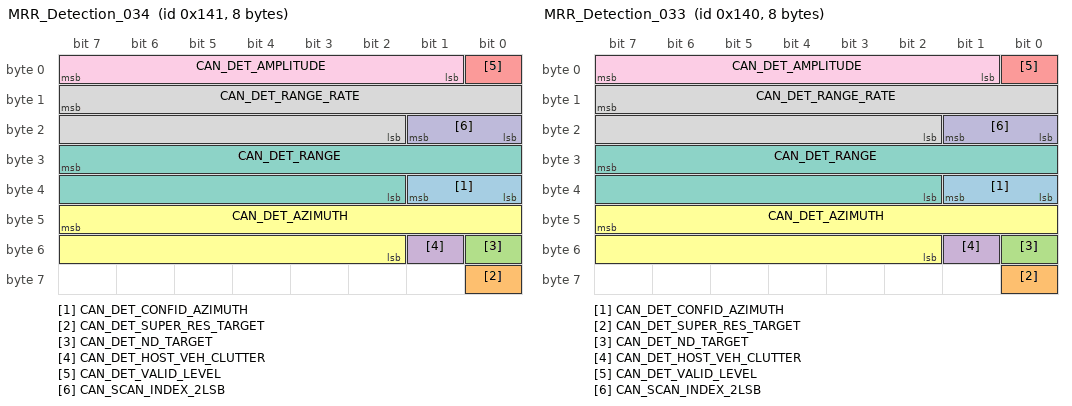
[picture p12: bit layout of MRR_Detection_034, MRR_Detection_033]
BO_ 321 MRR_Detection_034: 8 MRR
  SG_ CAN_DET_CONFID_AZIMUTH : 33|2@0+ (1,0) [0|3] "" IFV_VFP
  SG_ CAN_DET_SUPER_RES_TARGET : 56|1@0+ (1,0) [0|1] "" IFV_VFP
  SG_ CAN_DET_ND_TARGET : 48|1@0+ (1,0) [0|1] "" IFV_VFP
  SG_ CAN_DET_HOST_VEH_CLUTTER : 49|1@0+ (1,0) [0|1] "" IFV_VFP
  SG_ CAN_DET_VALID_LEVEL : 0|1@0+ (1,0) [0|1] "" IFV_VFP
  SG_ CAN_DET_AZIMUTH : 47|14@0+ (0.0003834,-3.1416) [-3.1416|3.13964] "rad" IFV_VFP
  SG_ CAN_DET_RANGE : 31|14@0+ (0.015625,0) [0|255.984] "m" IFV_VFP
  SG_ CAN_DET_RANGE_RATE : 15|14@0+ (0.015625,-128) [-128|127.984] "m/s" IFV_VFP
  SG_ CAN_DET_AMPLITUDE : 7|7@0+ (1,-64) [-64|63] "dBsm" IFV_VFP
  SG_ CAN_SCAN_INDEX_2LSB : 17|2@0+ (1,0) [0|3] "" IFV_VFP

BO_ 320 MRR_Detection_033: 8 MRR
  SG_ CAN_DET_CONFID_AZIMUTH : 33|2@0+ (1,0) [0|3] "" IFV_VFP
  SG_ CAN_DET_SUPER_RES_TARGET : 56|1@0+ (1,0) [0|1] "" IFV_VFP
  SG_ CAN_DET_ND_TARGET : 48|1@0+ (1,0) [0|1] "" IFV_VFP
  SG_ CAN_DET_HOST_VEH_CLUTTER : 49|1@0+ (1,0) [0|1] "" IFV_VFP
  SG_ CAN_DET_VALID_LEVEL : 0|1@0+ (1,0) [0|1] "" IFV_VFP
  SG_ CAN_DET_AZIMUTH : 47|14@0+ (0.0003834,-3.1416) [-3.1416|3.13964] "rad" IFV_VFP
  SG_ CAN_DET_RANGE : 31|14@0+ (0.015625,0) [0|255.984] "m" IFV_VFP
  SG_ CAN_DET_RANGE_RATE : 15|14@0+ (0.015625,-128) [-128|127.984] "m/s" IFV_VFP
  SG_ CAN_DET_AMPLITUDE : 7|7@0+ (1,-64) [-64|63] "dBsm" IFV_VFP
  SG_ CAN_SCAN_INDEX_2LSB : 17|2@0+ (1,0) [0|3] "" IFV_VFP

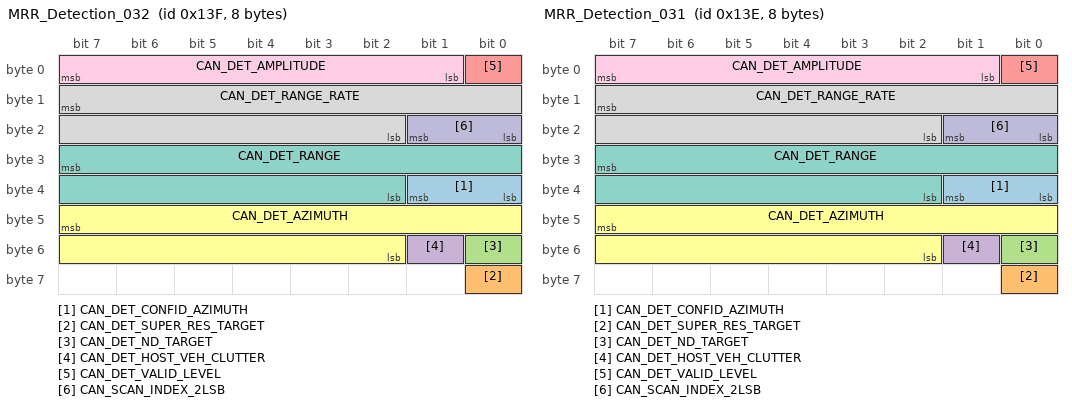
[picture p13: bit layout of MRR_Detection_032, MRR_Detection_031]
BO_ 319 MRR_Detection_032: 8 MRR
  SG_ CAN_DET_CONFID_AZIMUTH : 33|2@0+ (1,0) [0|3] "" IFV_VFP
  SG_ CAN_DET_SUPER_RES_TARGET : 56|1@0+ (1,0) [0|1] "" IFV_VFP
  SG_ CAN_DET_ND_TARGET : 48|1@0+ (1,0) [0|1] "" IFV_VFP
  SG_ CAN_DET_HOST_VEH_CLUTTER : 49|1@0+ (1,0) [0|1] "" IFV_VFP
  SG_ CAN_DET_VALID_LEVEL : 0|1@0+ (1,0) [0|1] "" IFV_VFP
  SG_ CAN_DET_AZIMUTH : 47|14@0+ (0.0003834,-3.1416) [-3.1416|3.13964] "rad" IFV_VFP
  SG_ CAN_DET_RANGE : 31|14@0+ (0.015625,0) [0|255.984] "m" IFV_VFP
  SG_ CAN_DET_RANGE_RATE : 15|14@0+ (0.015625,-128) [-128|127.984] "m/s" IFV_VFP
  SG_ CAN_DET_AMPLITUDE : 7|7@0+ (1,-64) [-64|63] "dBsm" IFV_VFP
  SG_ CAN_SCAN_INDEX_2LSB : 17|2@0+ (1,0) [0|3] "" IFV_VFP

BO_ 318 MRR_Detection_031: 8 MRR
  SG_ CAN_DET_CONFID_AZIMUTH : 33|2@0+ (1,0) [0|3] "" IFV_VFP
  SG_ CAN_DET_SUPER_RES_TARGET : 56|1@0+ (1,0) [0|1] "" IFV_VFP
  SG_ CAN_DET_ND_TARGET : 48|1@0+ (1,0) [0|1] "" IFV_VFP
  SG_ CAN_DET_HOST_VEH_CLUTTER : 49|1@0+ (1,0) [0|1] "" IFV_VFP
  SG_ CAN_DET_VALID_LEVEL : 0|1@0+ (1,0) [0|1] "" IFV_VFP
  SG_ CAN_DET_AZIMUTH : 47|14@0+ (0.0003834,-3.1416) [-3.1416|3.13964] "rad" IFV_VFP
  SG_ CAN_DET_RANGE : 31|14@0+ (0.015625,0) [0|255.984] "m" IFV_VFP
  SG_ CAN_DET_RANGE_RATE : 15|14@0+ (0.015625,-128) [-128|127.984] "m/s" IFV_VFP
  SG_ CAN_DET_AMPLITUDE : 7|7@0+ (1,-64) [-64|63] "dBsm" IFV_VFP
  SG_ CAN_SCAN_INDEX_2LSB : 17|2@0+ (1,0) [0|3] "" IFV_VFP

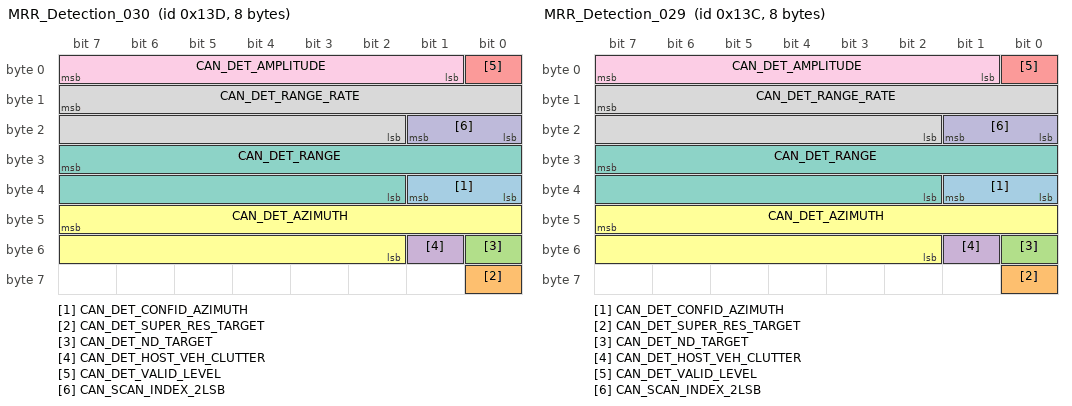
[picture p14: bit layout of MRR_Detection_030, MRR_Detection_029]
BO_ 317 MRR_Detection_030: 8 MRR
  SG_ CAN_DET_CONFID_AZIMUTH : 33|2@0+ (1,0) [0|3] "" IFV_VFP
  SG_ CAN_DET_SUPER_RES_TARGET : 56|1@0+ (1,0) [0|1] "" IFV_VFP
  SG_ CAN_DET_ND_TARGET : 48|1@0+ (1,0) [0|1] "" IFV_VFP
  SG_ CAN_DET_HOST_VEH_CLUTTER : 49|1@0+ (1,0) [0|1] "" IFV_VFP
  SG_ CAN_DET_VALID_LEVEL : 0|1@0+ (1,0) [0|1] "" IFV_VFP
  SG_ CAN_DET_AZIMUTH : 47|14@0+ (0.0003834,-3.1416) [-3.1416|3.13964] "rad" IFV_VFP
  SG_ CAN_DET_RANGE : 31|14@0+ (0.015625,0) [0|255.984] "m" IFV_VFP
  SG_ CAN_DET_RANGE_RATE : 15|14@0+ (0.015625,-128) [-128|127.984] "m/s" IFV_VFP
  SG_ CAN_DET_AMPLITUDE : 7|7@0+ (1,-64) [-64|63] "dBsm" IFV_VFP
  SG_ CAN_SCAN_INDEX_2LSB : 17|2@0+ (1,0) [0|3] "" IFV_VFP

BO_ 316 MRR_Detection_029: 8 MRR
  SG_ CAN_DET_CONFID_AZIMUTH : 33|2@0+ (1,0) [0|3] "" IFV_VFP
  SG_ CAN_DET_SUPER_RES_TARGET : 56|1@0+ (1,0) [0|1] "" IFV_VFP
  SG_ CAN_DET_ND_TARGET : 48|1@0+ (1,0) [0|1] "" IFV_VFP
  SG_ CAN_DET_HOST_VEH_CLUTTER : 49|1@0+ (1,0) [0|1] "" IFV_VFP
  SG_ CAN_DET_VALID_LEVEL : 0|1@0+ (1,0) [0|1] "" IFV_VFP
  SG_ CAN_DET_AZIMUTH : 47|14@0+ (0.0003834,-3.1416) [-3.1416|3.13964] "rad" IFV_VFP
  SG_ CAN_DET_RANGE : 31|14@0+ (0.015625,0) [0|255.984] "m" IFV_VFP
  SG_ CAN_DET_RANGE_RATE : 15|14@0+ (0.015625,-128) [-128|127.984] "m/s" IFV_VFP
  SG_ CAN_DET_AMPLITUDE : 7|7@0+ (1,-64) [-64|63] "dBsm" IFV_VFP
  SG_ CAN_SCAN_INDEX_2LSB : 17|2@0+ (1,0) [0|3] "" IFV_VFP

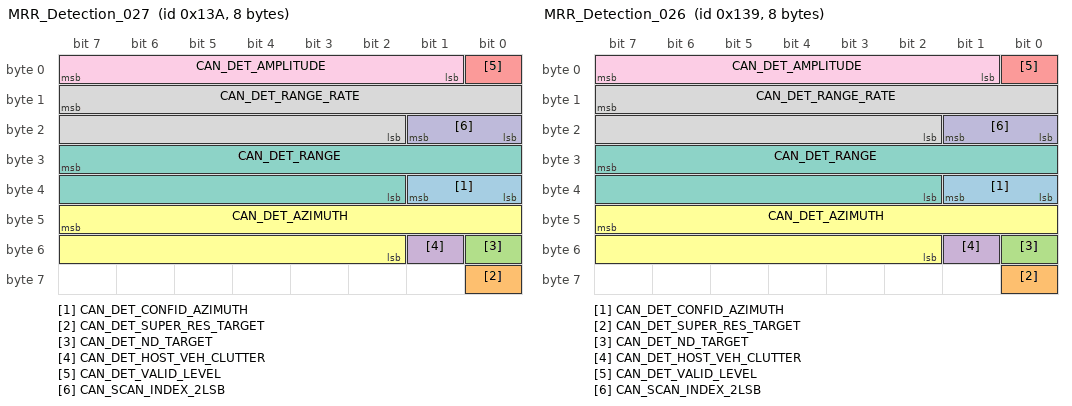
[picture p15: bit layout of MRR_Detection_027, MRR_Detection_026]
BO_ 314 MRR_Detection_027: 8 MRR
  SG_ CAN_DET_CONFID_AZIMUTH : 33|2@0+ (1,0) [0|3] "" IFV_VFP
  SG_ CAN_DET_SUPER_RES_TARGET : 56|1@0+ (1,0) [0|1] "" IFV_VFP
  SG_ CAN_DET_ND_TARGET : 48|1@0+ (1,0) [0|1] "" IFV_VFP
  SG_ CAN_DET_HOST_VEH_CLUTTER : 49|1@0+ (1,0) [0|1] "" IFV_VFP
  SG_ CAN_DET_VALID_LEVEL : 0|1@0+ (1,0) [0|1] "" IFV_VFP
  SG_ CAN_DET_AZIMUTH : 47|14@0+ (0.0003834,-3.1416) [-3.1416|3.13964] "rad" IFV_VFP
  SG_ CAN_DET_RANGE : 31|14@0+ (0.015625,0) [0|255.984] "m" IFV_VFP
  SG_ CAN_DET_RANGE_RATE : 15|14@0+ (0.015625,-128) [-128|127.984] "m/s" IFV_VFP
  SG_ CAN_DET_AMPLITUDE : 7|7@0+ (1,-64) [-64|63] "dBsm" IFV_VFP
  SG_ CAN_SCAN_INDEX_2LSB : 17|2@0+ (1,0) [0|3] "" IFV_VFP

BO_ 313 MRR_Detection_026: 8 MRR
  SG_ CAN_DET_CONFID_AZIMUTH : 33|2@0+ (1,0) [0|3] "" IFV_VFP
  SG_ CAN_DET_SUPER_RES_TARGET : 56|1@0+ (1,0) [0|1] "" IFV_VFP
  SG_ CAN_DET_ND_TARGET : 48|1@0+ (1,0) [0|1] "" IFV_VFP
  SG_ CAN_DET_HOST_VEH_CLUTTER : 49|1@0+ (1,0) [0|1] "" IFV_VFP
  SG_ CAN_DET_VALID_LEVEL : 0|1@0+ (1,0) [0|1] "" IFV_VFP
  SG_ CAN_DET_AZIMUTH : 47|14@0+ (0.0003834,-3.1416) [-3.1416|3.13964] "rad" IFV_VFP
  SG_ CAN_DET_RANGE : 31|14@0+ (0.015625,0) [0|255.984] "m" IFV_VFP
  SG_ CAN_DET_RANGE_RATE : 15|14@0+ (0.015625,-128) [-128|127.984] "m/s" IFV_VFP
  SG_ CAN_DET_AMPLITUDE : 7|7@0+ (1,-64) [-64|63] "dBsm" IFV_VFP
  SG_ CAN_SCAN_INDEX_2LSB : 17|2@0+ (1,0) [0|3] "" IFV_VFP

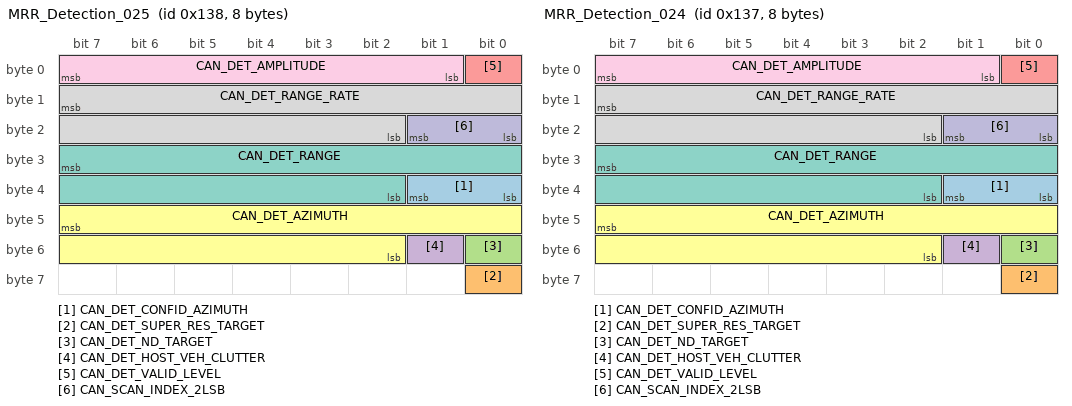
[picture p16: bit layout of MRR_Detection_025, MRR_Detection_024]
BO_ 312 MRR_Detection_025: 8 MRR
  SG_ CAN_DET_CONFID_AZIMUTH : 33|2@0+ (1,0) [0|3] "" IFV_VFP
  SG_ CAN_DET_SUPER_RES_TARGET : 56|1@0+ (1,0) [0|1] "" IFV_VFP
  SG_ CAN_DET_ND_TARGET : 48|1@0+ (1,0) [0|1] "" IFV_VFP
  SG_ CAN_DET_HOST_VEH_CLUTTER : 49|1@0+ (1,0) [0|1] "" IFV_VFP
  SG_ CAN_DET_VALID_LEVEL : 0|1@0+ (1,0) [0|1] "" IFV_VFP
  SG_ CAN_DET_AZIMUTH : 47|14@0+ (0.0003834,-3.1416) [-3.1416|3.13964] "rad" IFV_VFP
  SG_ CAN_DET_RANGE : 31|14@0+ (0.015625,0) [0|255.984] "m" IFV_VFP
  SG_ CAN_DET_RANGE_RATE : 15|14@0+ (0.015625,-128) [-128|127.984] "m/s" IFV_VFP
  SG_ CAN_DET_AMPLITUDE : 7|7@0+ (1,-64) [-64|63] "dBsm" IFV_VFP
  SG_ CAN_SCAN_INDEX_2LSB : 17|2@0+ (1,0) [0|3] "" IFV_VFP

BO_ 311 MRR_Detection_024: 8 MRR
  SG_ CAN_DET_CONFID_AZIMUTH : 33|2@0+ (1,0) [0|3] "" IFV_VFP
  SG_ CAN_DET_SUPER_RES_TARGET : 56|1@0+ (1,0) [0|1] "" IFV_VFP
  SG_ CAN_DET_ND_TARGET : 48|1@0+ (1,0) [0|1] "" IFV_VFP
  SG_ CAN_DET_HOST_VEH_CLUTTER : 49|1@0+ (1,0) [0|1] "" IFV_VFP
  SG_ CAN_DET_VALID_LEVEL : 0|1@0+ (1,0) [0|1] "" IFV_VFP
  SG_ CAN_DET_AZIMUTH : 47|14@0+ (0.0003834,-3.1416) [-3.1416|3.13964] "rad" IFV_VFP
  SG_ CAN_DET_RANGE : 31|14@0+ (0.015625,0) [0|255.984] "m" IFV_VFP
  SG_ CAN_DET_RANGE_RATE : 15|14@0+ (0.015625,-128) [-128|127.984] "m/s" IFV_VFP
  SG_ CAN_DET_AMPLITUDE : 7|7@0+ (1,-64) [-64|63] "dBsm" IFV_VFP
  SG_ CAN_SCAN_INDEX_2LSB : 17|2@0+ (1,0) [0|3] "" IFV_VFP

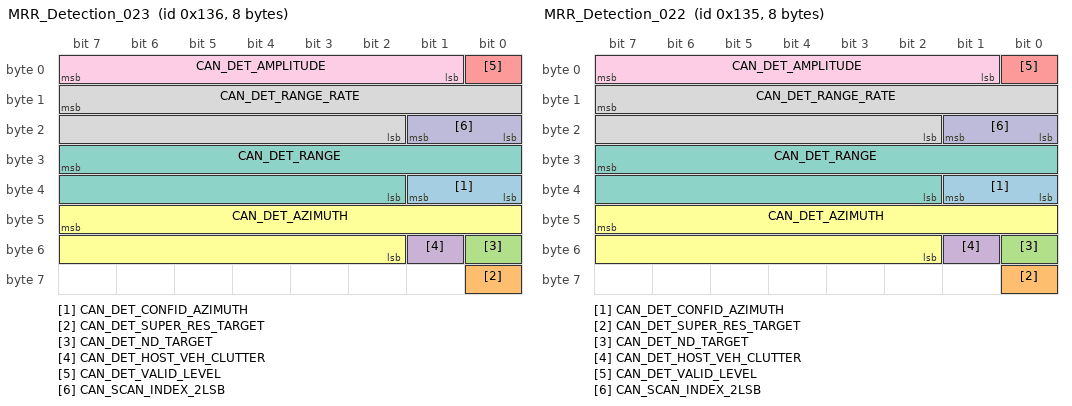
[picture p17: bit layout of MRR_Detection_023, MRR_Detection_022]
BO_ 310 MRR_Detection_023: 8 MRR
  SG_ CAN_DET_CONFID_AZIMUTH : 33|2@0+ (1,0) [0|3] "" IFV_VFP
  SG_ CAN_DET_SUPER_RES_TARGET : 56|1@0+ (1,0) [0|1] "" IFV_VFP
  SG_ CAN_DET_ND_TARGET : 48|1@0+ (1,0) [0|1] "" IFV_VFP
  SG_ CAN_DET_HOST_VEH_CLUTTER : 49|1@0+ (1,0) [0|1] "" IFV_VFP
  SG_ CAN_DET_VALID_LEVEL : 0|1@0+ (1,0) [0|1] "" IFV_VFP
  SG_ CAN_DET_AZIMUTH : 47|14@0+ (0.0003834,-3.1416) [-3.1416|3.13964] "rad" IFV_VFP
  SG_ CAN_DET_RANGE : 31|14@0+ (0.015625,0) [0|255.984] "m" IFV_VFP
  SG_ CAN_DET_RANGE_RATE : 15|14@0+ (0.015625,-128) [-128|127.984] "m/s" IFV_VFP
  SG_ CAN_DET_AMPLITUDE : 7|7@0+ (1,-64) [-64|63] "dBsm" IFV_VFP
  SG_ CAN_SCAN_INDEX_2LSB : 17|2@0+ (1,0) [0|3] "" IFV_VFP

BO_ 309 MRR_Detection_022: 8 MRR
  SG_ CAN_DET_CONFID_AZIMUTH : 33|2@0+ (1,0) [0|3] "" IFV_VFP
  SG_ CAN_DET_SUPER_RES_TARGET : 56|1@0+ (1,0) [0|1] "" IFV_VFP
  SG_ CAN_DET_ND_TARGET : 48|1@0+ (1,0) [0|1] "" IFV_VFP
  SG_ CAN_DET_HOST_VEH_CLUTTER : 49|1@0+ (1,0) [0|1] "" IFV_VFP
  SG_ CAN_DET_VALID_LEVEL : 0|1@0+ (1,0) [0|1] "" IFV_VFP
  SG_ CAN_DET_AZIMUTH : 47|14@0+ (0.0003834,-3.1416) [-3.1416|3.13964] "rad" IFV_VFP
  SG_ CAN_DET_RANGE : 31|14@0+ (0.015625,0) [0|255.984] "m" IFV_VFP
  SG_ CAN_DET_RANGE_RATE : 15|14@0+ (0.015625,-128) [-128|127.984] "m/s" IFV_VFP
  SG_ CAN_DET_AMPLITUDE : 7|7@0+ (1,-64) [-64|63] "dBsm" IFV_VFP
  SG_ CAN_SCAN_INDEX_2LSB : 17|2@0+ (1,0) [0|3] "" IFV_VFP

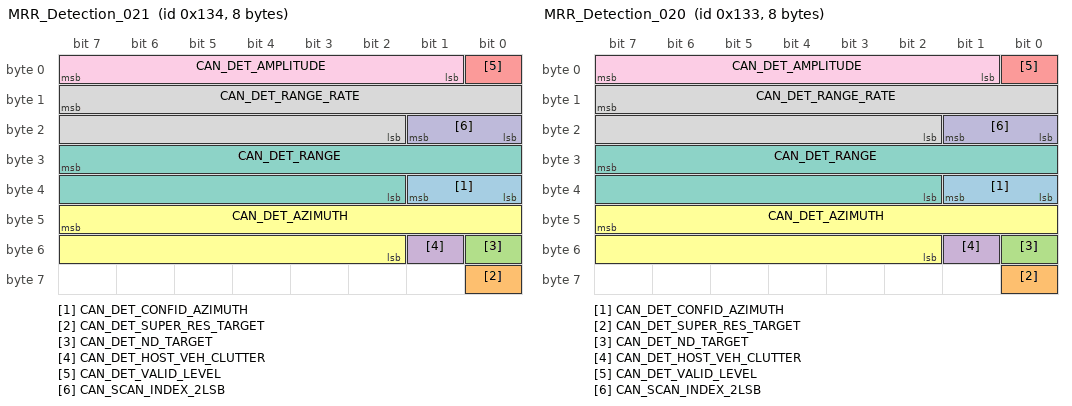
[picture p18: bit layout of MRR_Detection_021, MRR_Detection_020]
BO_ 308 MRR_Detection_021: 8 MRR
  SG_ CAN_DET_CONFID_AZIMUTH : 33|2@0+ (1,0) [0|3] "" IFV_VFP
  SG_ CAN_DET_SUPER_RES_TARGET : 56|1@0+ (1,0) [0|1] "" IFV_VFP
  SG_ CAN_DET_ND_TARGET : 48|1@0+ (1,0) [0|1] "" IFV_VFP
  SG_ CAN_DET_HOST_VEH_CLUTTER : 49|1@0+ (1,0) [0|1] "" IFV_VFP
  SG_ CAN_DET_VALID_LEVEL : 0|1@0+ (1,0) [0|1] "" IFV_VFP
  SG_ CAN_DET_AZIMUTH : 47|14@0+ (0.0003834,-3.1416) [-3.1416|3.13964] "rad" IFV_VFP
  SG_ CAN_DET_RANGE : 31|14@0+ (0.015625,0) [0|255.984] "m" IFV_VFP
  SG_ CAN_DET_RANGE_RATE : 15|14@0+ (0.015625,-128) [-128|127.984] "m/s" IFV_VFP
  SG_ CAN_DET_AMPLITUDE : 7|7@0+ (1,-64) [-64|63] "dBsm" IFV_VFP
  SG_ CAN_SCAN_INDEX_2LSB : 17|2@0+ (1,0) [0|3] "" IFV_VFP

BO_ 307 MRR_Detection_020: 8 MRR
  SG_ CAN_DET_CONFID_AZIMUTH : 33|2@0+ (1,0) [0|3] "" IFV_VFP
  SG_ CAN_DET_SUPER_RES_TARGET : 56|1@0+ (1,0) [0|1] "" IFV_VFP
  SG_ CAN_DET_ND_TARGET : 48|1@0+ (1,0) [0|1] "" IFV_VFP
  SG_ CAN_DET_HOST_VEH_CLUTTER : 49|1@0+ (1,0) [0|1] "" IFV_VFP
  SG_ CAN_DET_VALID_LEVEL : 0|1@0+ (1,0) [0|1] "" IFV_VFP
  SG_ CAN_DET_AZIMUTH : 47|14@0+ (0.0003834,-3.1416) [-3.1416|3.13964] "rad" IFV_VFP
  SG_ CAN_DET_RANGE : 31|14@0+ (0.015625,0) [0|255.984] "m" IFV_VFP
  SG_ CAN_DET_RANGE_RATE : 15|14@0+ (0.015625,-128) [-128|127.984] "m/s" IFV_VFP
  SG_ CAN_DET_AMPLITUDE : 7|7@0+ (1,-64) [-64|63] "dBsm" IFV_VFP
  SG_ CAN_SCAN_INDEX_2LSB : 17|2@0+ (1,0) [0|3] "" IFV_VFP

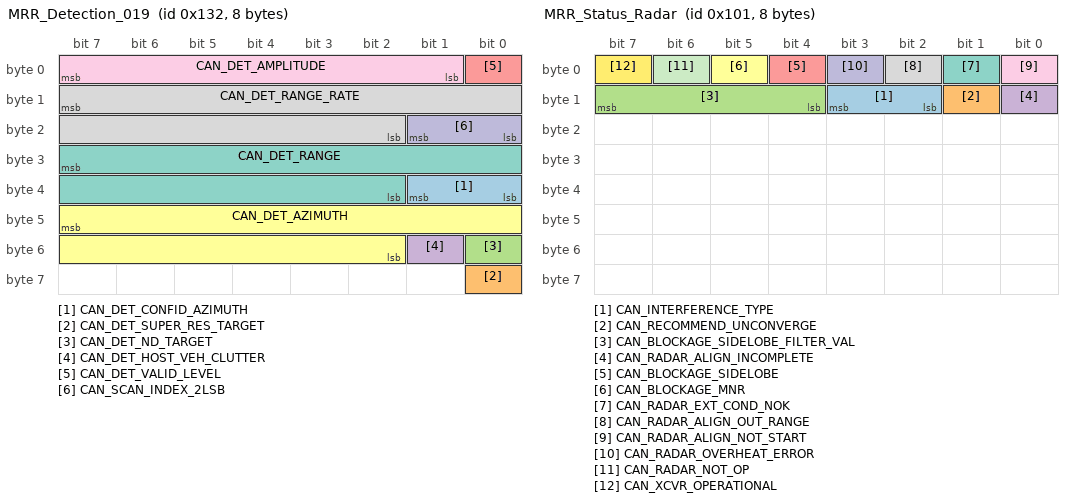
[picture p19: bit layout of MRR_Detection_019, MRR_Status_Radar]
BO_ 306 MRR_Detection_019: 8 MRR
  SG_ CAN_DET_CONFID_AZIMUTH : 33|2@0+ (1,0) [0|3] "" IFV_VFP
  SG_ CAN_DET_SUPER_RES_TARGET : 56|1@0+ (1,0) [0|1] "" IFV_VFP
  SG_ CAN_DET_ND_TARGET : 48|1@0+ (1,0) [0|1] "" IFV_VFP
  SG_ CAN_DET_HOST_VEH_CLUTTER : 49|1@0+ (1,0) [0|1] "" IFV_VFP
  SG_ CAN_DET_VALID_LEVEL : 0|1@0+ (1,0) [0|1] "" IFV_VFP
  SG_ CAN_DET_AZIMUTH : 47|14@0+ (0.0003834,-3.1416) [-3.1416|3.13964] "rad" IFV_VFP
  SG_ CAN_DET_RANGE : 31|14@0+ (0.015625,0) [0|255.984] "m" IFV_VFP
  SG_ CAN_DET_RANGE_RATE : 15|14@0+ (0.015625,-128) [-128|127.984] "m/s" IFV_VFP
  SG_ CAN_DET_AMPLITUDE : 7|7@0+ (1,-64) [-64|63] "dBsm" IFV_VFP
  SG_ CAN_SCAN_INDEX_2LSB : 17|2@0+ (1,0) [0|3] "" IFV_VFP

BO_ 305 MRR_Detection_018: 8 MRR
  SG_ CAN_DET_CONFID_AZIMUTH : 33|2@0+ (1,0) [0|3] "" IFV_VFP
  SG_ CAN_DET_SUPER_RES_TARGET : 56|1@0+ (1,0) [0|1] "" IFV_VFP
  SG_ CAN_DET_ND_TARGET : 48|1@0+ (1,0) [0|1] "" IFV_VFP
  SG_ CAN_DET_HOST_VEH_CLUTTER : 49|1@0+ (1,0) [0|1] "" IFV_VFP
  SG_ CAN_DET_VALID_LEVEL : 0|1@0+ (1,0) [0|1] "" IFV_VFP
  SG_ CAN_DET_AZIMUTH : 47|14@0+ (0.0003834,-3.1416) [-3.1416|3.13964] "rad" IFV_VFP
  SG_ CAN_DET_RANGE : 31|14@0+ (0.015625,0) [0|255.984] "m" IFV_VFP
  SG_ CAN_DET_RANGE_RATE : 15|14@0+ (0.015625,-128) [-128|127.984] "m/s" IFV_VFP
  SG_ CAN_DET_AMPLITUDE : 7|7@0+ (1,-64) [-64|63] "dBsm" IFV_VFP
  SG_ CAN_SCAN_INDEX_2LSB : 17|2@0+ (1,0) [0|3] "" IFV_VFP

BO_ 341 MRR_Detection_054: 8 MRR
  SG_ CAN_DET_CONFID_AZIMUTH : 33|2@0+ (1,0) [0|3] "" IFV_VFP
  SG_ CAN_DET_SUPER_RES_TARGET : 56|1@0+ (1,0) [0|1] "" IFV_VFP
  SG_ CAN_DET_ND_TARGET : 48|1@0+ (1,0) [0|1] "" IFV_VFP
  SG_ CAN_DET_HOST_VEH_CLUTTER : 49|1@0+ (1,0) [0|1] "" IFV_VFP
  SG_ CAN_DET_VALID_LEVEL : 0|1@0+ (1,0) [0|1] "" IFV_VFP
  SG_ CAN_DET_AZIMUTH : 47|14@0+ (0.0003834,-3.1416) [-3.1416|3.13964] "rad" IFV_VFP
  SG_ CAN_DET_RANGE : 31|14@0+ (0.015625,0) [0|255.984] "m" IFV_VFP
  SG_ CAN_DET_RANGE_RATE : 15|14@0+ (0.015625,-128) [-128|127.984] "m/s" IFV_VFP
  SG_ CAN_DET_AMPLITUDE : 7|7@0+ (1,-64) [-64|63] "dBsm" IFV_VFP
  SG_ CAN_SCAN_INDEX_2LSB : 17|2@0+ (1,0) [0|3] "" IFV_VFP

BO_ 340 MRR_Detection_053: 8 MRR
  SG_ CAN_DET_CONFID_AZIMUTH : 33|2@0+ (1,0) [0|3] "" IFV_VFP
  SG_ CAN_DET_SUPER_RES_TARGET : 56|1@0+ (1,0) [0|1] "" IFV_VFP
  SG_ CAN_DET_ND_TARGET : 48|1@0+ (1,0) [0|1] "" IFV_VFP
  SG_ CAN_DET_HOST_VEH_CLUTTER : 49|1@0+ (1,0) [0|1] "" IFV_VFP
  SG_ CAN_DET_VALID_LEVEL : 0|1@0+ (1,0) [0|1] "" IFV_VFP
  SG_ CAN_DET_AZIMUTH : 47|14@0+ (0.0003834,-3.1416) [-3.1416|3.13964] "rad" IFV_VFP
  SG_ CAN_DET_RANGE : 31|14@0+ (0.015625,0) [0|255.984] "m" IFV_VFP
  SG_ CAN_DET_RANGE_RATE : 15|14@0+ (0.015625,-128) [-128|127.984] "m/s" IFV_VFP
  SG_ CAN_DET_AMPLITUDE : 7|7@0+ (1,-64) [-64|63] "dBsm" IFV_VFP
  SG_ CAN_SCAN_INDEX_2LSB : 17|2@0+ (1,0) [0|3] "" IFV_VFP

BO_ 339 MRR_Detection_052: 8 MRR
  SG_ CAN_DET_CONFID_AZIMUTH : 33|2@0+ (1,0) [0|3] "" IFV_VFP
  SG_ CAN_DET_SUPER_RES_TARGET : 56|1@0+ (1,0) [0|1] "" IFV_VFP
  SG_ CAN_DET_ND_TARGET : 48|1@0+ (1,0) [0|1] "" IFV_VFP
  SG_ CAN_DET_HOST_VEH_CLUTTER : 49|1@0+ (1,0) [0|1] "" IFV_VFP
  SG_ CAN_DET_VALID_LEVEL : 0|1@0+ (1,0) [0|1] "" IFV_VFP
  SG_ CAN_DET_AZIMUTH : 47|14@0+ (0.0003834,-3.1416) [-3.1416|3.13964] "rad" IFV_VFP
  SG_ CAN_DET_RANGE : 31|14@0+ (0.015625,0) [0|255.984] "m" IFV_VFP
  SG_ CAN_DET_RANGE_RATE : 15|14@0+ (0.015625,-128) [-128|127.984] "m/s" IFV_VFP
  SG_ CAN_DET_AMPLITUDE : 7|7@0+ (1,-64) [-64|63] "dBsm" IFV_VFP
  SG_ CAN_SCAN_INDEX_2LSB : 17|2@0+ (1,0) [0|3] "" IFV_VFP

BO_ 338 MRR_Detection_051: 8 MRR
  SG_ CAN_DET_CONFID_AZIMUTH : 33|2@0+ (1,0) [0|3] "" IFV_VFP
  SG_ CAN_DET_SUPER_RES_TARGET : 56|1@0+ (1,0) [0|1] "" IFV_VFP
  SG_ CAN_DET_ND_TARGET : 48|1@0+ (1,0) [0|1] "" IFV_VFP
  SG_ CAN_DET_HOST_VEH_CLUTTER : 49|1@0+ (1,0) [0|1] "" IFV_VFP
  SG_ CAN_DET_VALID_LEVEL : 0|1@0+ (1,0) [0|1] "" IFV_VFP
  SG_ CAN_DET_AZIMUTH : 47|14@0+ (0.0003834,-3.1416) [-3.1416|3.13964] "rad" IFV_VFP
  SG_ CAN_DET_RANGE : 31|14@0+ (0.015625,0) [0|255.984] "m" IFV_VFP
  SG_ CAN_DET_RANGE_RATE : 15|14@0+ (0.015625,-128) [-128|127.984] "m/s" IFV_VFP
  SG_ CAN_DET_AMPLITUDE : 7|7@0+ (1,-64) [-64|63] "dBsm" IFV_VFP
  SG_ CAN_SCAN_INDEX_2LSB : 17|2@0+ (1,0) [0|3] "" IFV_VFP

BO_ 337 MRR_Detection_050: 8 MRR
  SG_ CAN_DET_CONFID_AZIMUTH : 33|2@0+ (1,0) [0|3] "" IFV_VFP
  SG_ CAN_DET_SUPER_RES_TARGET : 56|1@0+ (1,0) [0|1] "" IFV_VFP
  SG_ CAN_DET_ND_TARGET : 48|1@0+ (1,0) [0|1] "" IFV_VFP
  SG_ CAN_DET_HOST_VEH_CLUTTER : 49|1@0+ (1,0) [0|1] "" IFV_VFP
  SG_ CAN_DET_VALID_LEVEL : 0|1@0+ (1,0) [0|1] "" IFV_VFP
  SG_ CAN_DET_AZIMUTH : 47|14@0+ (0.0003834,-3.1416) [-3.1416|3.13964] "rad" IFV_VFP
  SG_ CAN_DET_RANGE : 31|14@0+ (0.015625,0) [0|255.984] "m" IFV_VFP
  SG_ CAN_DET_RANGE_RATE : 15|14@0+ (0.015625,-128) [-128|127.984] "m/s" IFV_VFP
  SG_ CAN_DET_AMPLITUDE : 7|7@0+ (1,-64) [-64|63] "dBsm" IFV_VFP
  SG_ CAN_SCAN_INDEX_2LSB : 17|2@0+ (1,0) [0|3] "" IFV_VFP

BO_ 336 MRR_Detection_049: 8 MRR
  SG_ CAN_DET_CONFID_AZIMUTH : 33|2@0+ (1,0) [0|3] "" IFV_VFP
  SG_ CAN_DET_SUPER_RES_TARGET : 56|1@0+ (1,0) [0|1] "" IFV_VFP
  SG_ CAN_DET_ND_TARGET : 48|1@0+ (1,0) [0|1] "" IFV_VFP
  SG_ CAN_DET_HOST_VEH_CLUTTER : 49|1@0+ (1,0) [0|1] "" IFV_VFP
  SG_ CAN_DET_VALID_LEVEL : 0|1@0+ (1,0) [0|1] "" IFV_VFP
  SG_ CAN_DET_AZIMUTH : 47|14@0+ (0.0003834,-3.1416) [-3.1416|3.13964] "rad" IFV_VFP
  SG_ CAN_DET_RANGE : 31|14@0+ (0.015625,0) [0|255.984] "m" IFV_VFP
  SG_ CAN_DET_RANGE_RATE : 15|14@0+ (0.015625,-128) [-128|127.984] "m/s" IFV_VFP
  SG_ CAN_DET_AMPLITUDE : 7|7@0+ (1,-64) [-64|63] "dBsm" IFV_VFP
  SG_ CAN_SCAN_INDEX_2LSB : 17|2@0+ (1,0) [0|3] "" IFV_VFP

BO_ 326 MRR_Detection_039: 8 MRR
  SG_ CAN_DET_CONFID_AZIMUTH : 33|2@0+ (1,0) [0|3] "" IFV_VFP
  SG_ CAN_DET_SUPER_RES_TARGET : 56|1@0+ (1,0) [0|1] "" IFV_VFP
  SG_ CAN_DET_ND_TARGET : 48|1@0+ (1,0) [0|1] "" IFV_VFP
  SG_ CAN_DET_HOST_VEH_CLUTTER : 49|1@0+ (1,0) [0|1] "" IFV_VFP
  SG_ CAN_DET_VALID_LEVEL : 0|1@0+ (1,0) [0|1] "" IFV_VFP
  SG_ CAN_DET_AZIMUTH : 47|14@0+ (0.0003834,-3.1416) [-3.1416|3.13964] "rad" IFV_VFP
  SG_ CAN_DET_RANGE : 31|14@0+ (0.015625,0) [0|255.984] "m" IFV_VFP
  SG_ CAN_DET_RANGE_RATE : 15|14@0+ (0.015625,-128) [-128|127.984] "m/s" IFV_VFP
  SG_ CAN_DET_AMPLITUDE : 7|7@0+ (1,-64) [-64|63] "dBsm" IFV_VFP
  SG_ CAN_SCAN_INDEX_2LSB : 17|2@0+ (1,0) [0|3] "" IFV_VFP

BO_ 315 MRR_Detection_028: 8 MRR
  SG_ CAN_DET_CONFID_AZIMUTH : 33|2@0+ (1,0) [0|3] "" IFV_VFP
  SG_ CAN_DET_SUPER_RES_TARGET : 56|1@0+ (1,0) [0|1] "" IFV_VFP
  SG_ CAN_DET_ND_TARGET : 48|1@0+ (1,0) [0|1] "" IFV_VFP
  SG_ CAN_DET_HOST_VEH_CLUTTER : 49|1@0+ (1,0) [0|1] "" IFV_VFP
  SG_ CAN_DET_VALID_LEVEL : 0|1@0+ (1,0) [0|1] "" IFV_VFP
  SG_ CAN_DET_AZIMUTH : 47|14@0+ (0.0003834,-3.1416) [-3.1416|3.13964] "rad" IFV_VFP
  SG_ CAN_DET_RANGE : 31|14@0+ (0.015625,0) [0|255.984] "m" IFV_VFP
  SG_ CAN_DET_RANGE_RATE : 15|14@0+ (0.015625,-128) [-128|127.984] "m/s" IFV_VFP
  SG_ CAN_DET_AMPLITUDE : 7|7@0+ (1,-64) [-64|63] "dBsm" IFV_VFP
  SG_ CAN_SCAN_INDEX_2LSB : 17|2@0+ (1,0) [0|3] "" IFV_VFP

BO_ 304 MRR_Detection_017: 8 MRR
  SG_ CAN_DET_CONFID_AZIMUTH : 33|2@0+ (1,0) [0|3] "" IFV_VFP
  SG_ CAN_DET_SUPER_RES_TARGET : 56|1@0+ (1,0) [0|1] "" IFV_VFP
  SG_ CAN_DET_ND_TARGET : 48|1@0+ (1,0) [0|1] "" IFV_VFP
  SG_ CAN_DET_HOST_VEH_CLUTTER : 49|1@0+ (1,0) [0|1] "" IFV_VFP
  SG_ CAN_DET_VALID_LEVEL : 0|1@0+ (1,0) [0|1] "" IFV_VFP
  SG_ CAN_DET_AZIMUTH : 47|14@0+ (0.0003834,-3.1416) [-3.1416|3.13964] "rad" IFV_VFP
  SG_ CAN_DET_RANGE : 31|14@0+ (0.015625,0) [0|255.984] "m" IFV_VFP
  SG_ CAN_DET_RANGE_RATE : 15|14@0+ (0.015625,-128) [-128|127.984] "m/s" IFV_VFP
  SG_ CAN_DET_AMPLITUDE : 7|7@0+ (1,-64) [-64|63] "dBsm" IFV_VFP
  SG_ CAN_SCAN_INDEX_2LSB : 17|2@0+ (1,0) [0|3] "" IFV_VFP

BO_ 303 MRR_Detection_016: 8 MRR
  SG_ CAN_DET_CONFID_AZIMUTH : 33|2@0+ (1,0) [0|3] "" IFV_VFP
  SG_ CAN_DET_SUPER_RES_TARGET : 56|1@0+ (1,0) [0|1] "" IFV_VFP
  SG_ CAN_DET_ND_TARGET : 48|1@0+ (1,0) [0|1] "" IFV_VFP
  SG_ CAN_DET_HOST_VEH_CLUTTER : 49|1@0+ (1,0) [0|1] "" IFV_VFP
  SG_ CAN_DET_VALID_LEVEL : 0|1@0+ (1,0) [0|1] "" IFV_VFP
  SG_ CAN_DET_AZIMUTH : 47|14@0+ (0.0003834,-3.1416) [-3.1416|3.13964] "rad" IFV_VFP
  SG_ CAN_DET_RANGE : 31|14@0+ (0.015625,0) [0|255.984] "m" IFV_VFP
  SG_ CAN_DET_RANGE_RATE : 15|14@0+ (0.015625,-128) [-128|127.984] "m/s" IFV_VFP
  SG_ CAN_DET_AMPLITUDE : 7|7@0+ (1,-64) [-64|63] "dBsm" IFV_VFP
  SG_ CAN_SCAN_INDEX_2LSB : 17|2@0+ (1,0) [0|3] "" IFV_VFP

BO_ 302 MRR_Detection_015: 8 MRR
  SG_ CAN_DET_CONFID_AZIMUTH : 33|2@0+ (1,0) [0|3] "" IFV_VFP
  SG_ CAN_DET_SUPER_RES_TARGET : 56|1@0+ (1,0) [0|1] "" IFV_VFP
  SG_ CAN_DET_ND_TARGET : 48|1@0+ (1,0) [0|1] "" IFV_VFP
  SG_ CAN_DET_HOST_VEH_CLUTTER : 49|1@0+ (1,0) [0|1] "" IFV_VFP
  SG_ CAN_DET_VALID_LEVEL : 0|1@0+ (1,0) [0|1] "" IFV_VFP
  SG_ CAN_DET_AZIMUTH : 47|14@0+ (0.0003834,-3.1416) [-3.1416|3.13964] "rad" IFV_VFP
  SG_ CAN_DET_RANGE : 31|14@0+ (0.015625,0) [0|255.984] "m" IFV_VFP
  SG_ CAN_DET_RANGE_RATE : 15|14@0+ (0.015625,-128) [-128|127.984] "m/s" IFV_VFP
  SG_ CAN_DET_AMPLITUDE : 7|7@0+ (1,-64) [-64|63] "dBsm" IFV_VFP
  SG_ CAN_SCAN_INDEX_2LSB : 17|2@0+ (1,0) [0|3] "" IFV_VFP

BO_ 301 MRR_Detection_014: 8 MRR
  SG_ CAN_DET_CONFID_AZIMUTH : 33|2@0+ (1,0) [0|3] "" IFV_VFP
  SG_ CAN_DET_SUPER_RES_TARGET : 56|1@0+ (1,0) [0|1] "" IFV_VFP
  SG_ CAN_DET_ND_TARGET : 48|1@0+ (1,0) [0|1] "" IFV_VFP
  SG_ CAN_DET_HOST_VEH_CLUTTER : 49|1@0+ (1,0) [0|1] "" IFV_VFP
  SG_ CAN_DET_VALID_LEVEL : 0|1@0+ (1,0) [0|1] "" IFV_VFP
  SG_ CAN_DET_AZIMUTH : 47|14@0+ (0.0003834,-3.1416) [-3.1416|3.13964] "rad" IFV_VFP
  SG_ CAN_DET_RANGE : 31|14@0+ (0.015625,0) [0|255.984] "m" IFV_VFP
  SG_ CAN_DET_RANGE_RATE : 15|14@0+ (0.015625,-128) [-128|127.984] "m/s" IFV_VFP
  SG_ CAN_DET_AMPLITUDE : 7|7@0+ (1,-64) [-64|63] "dBsm" IFV_VFP
  SG_ CAN_SCAN_INDEX_2LSB : 17|2@0+ (1,0) [0|3] "" IFV_VFP

BO_ 300 MRR_Detection_013: 8 MRR
  SG_ CAN_DET_CONFID_AZIMUTH : 33|2@0+ (1,0) [0|3] "" IFV_VFP
  SG_ CAN_DET_SUPER_RES_TARGET : 56|1@0+ (1,0) [0|1] "" IFV_VFP
  SG_ CAN_DET_ND_TARGET : 48|1@0+ (1,0) [0|1] "" IFV_VFP
  SG_ CAN_DET_HOST_VEH_CLUTTER : 49|1@0+ (1,0) [0|1] "" IFV_VFP
  SG_ CAN_DET_VALID_LEVEL : 0|1@0+ (1,0) [0|1] "" IFV_VFP
  SG_ CAN_DET_AZIMUTH : 47|14@0+ (0.0003834,-3.1416) [-3.1416|3.13964] "rad" IFV_VFP
  SG_ CAN_DET_RANGE : 31|14@0+ (0.015625,0) [0|255.984] "m" IFV_VFP
  SG_ CAN_DET_RANGE_RATE : 15|14@0+ (0.015625,-128) [-128|127.984] "m/s" IFV_VFP
  SG_ CAN_DET_AMPLITUDE : 7|7@0+ (1,-64) [-64|63] "dBsm" IFV_VFP
  SG_ CAN_SCAN_INDEX_2LSB : 17|2@0+ (1,0) [0|3] "" IFV_VFP

BO_ 299 MRR_Detection_012: 8 MRR
  SG_ CAN_DET_CONFID_AZIMUTH : 33|2@0+ (1,0) [0|3] "" IFV_VFP
  SG_ CAN_DET_SUPER_RES_TARGET : 56|1@0+ (1,0) [0|1] "" IFV_VFP
  SG_ CAN_DET_ND_TARGET : 48|1@0+ (1,0) [0|1] "" IFV_VFP
  SG_ CAN_DET_HOST_VEH_CLUTTER : 49|1@0+ (1,0) [0|1] "" IFV_VFP
  SG_ CAN_DET_VALID_LEVEL : 0|1@0+ (1,0) [0|1] "" IFV_VFP
  SG_ CAN_DET_AZIMUTH : 47|14@0+ (0.0003834,-3.1416) [-3.1416|3.13964] "rad" IFV_VFP
  SG_ CAN_DET_RANGE : 31|14@0+ (0.015625,0) [0|255.984] "m" IFV_VFP
  SG_ CAN_DET_RANGE_RATE : 15|14@0+ (0.015625,-128) [-128|127.984] "m/s" IFV_VFP
  SG_ CAN_DET_AMPLITUDE : 7|7@0+ (1,-64) [-64|63] "dBsm" IFV_VFP
  SG_ CAN_SCAN_INDEX_2LSB : 17|2@0+ (1,0) [0|3] "" IFV_VFP

BO_ 298 MRR_Detection_011: 8 MRR
  SG_ CAN_DET_CONFID_AZIMUTH : 33|2@0+ (1,0) [0|3] "" IFV_VFP
  SG_ CAN_DET_SUPER_RES_TARGET : 56|1@0+ (1,0) [0|1] "" IFV_VFP
  SG_ CAN_DET_ND_TARGET : 48|1@0+ (1,0) [0|1] "" IFV_VFP
  SG_ CAN_DET_HOST_VEH_CLUTTER : 49|1@0+ (1,0) [0|1] "" IFV_VFP
  SG_ CAN_DET_VALID_LEVEL : 0|1@0+ (1,0) [0|1] "" IFV_VFP
  SG_ CAN_DET_AZIMUTH : 47|14@0+ (0.0003834,-3.1416) [-3.1416|3.13964] "rad" IFV_VFP
  SG_ CAN_DET_RANGE : 31|14@0+ (0.015625,0) [0|255.984] "m" IFV_VFP
  SG_ CAN_DET_RANGE_RATE : 15|14@0+ (0.015625,-128) [-128|127.984] "m/s" IFV_VFP
  SG_ CAN_DET_AMPLITUDE : 7|7@0+ (1,-64) [-64|63] "dBsm" IFV_VFP
  SG_ CAN_SCAN_INDEX_2LSB : 17|2@0+ (1,0) [0|3] "" IFV_VFP

BO_ 297 MRR_Detection_010: 8 MRR
  SG_ CAN_DET_CONFID_AZIMUTH : 33|2@0+ (1,0) [0|3] "" IFV_VFP
  SG_ CAN_DET_SUPER_RES_TARGET : 56|1@0+ (1,0) [0|1] "" IFV_VFP
  SG_ CAN_DET_ND_TARGET : 48|1@0+ (1,0) [0|1] "" IFV_VFP
  SG_ CAN_DET_HOST_VEH_CLUTTER : 49|1@0+ (1,0) [0|1] "" IFV_VFP
  SG_ CAN_DET_VALID_LEVEL : 0|1@0+ (1,0) [0|1] "" IFV_VFP
  SG_ CAN_DET_AZIMUTH : 47|14@0+ (0.0003834,-3.1416) [-3.1416|3.13964] "rad" IFV_VFP
  SG_ CAN_DET_RANGE : 31|14@0+ (0.015625,0) [0|255.984] "m" IFV_VFP
  SG_ CAN_DET_RANGE_RATE : 15|14@0+ (0.015625,-128) [-128|127.984] "m/s" IFV_VFP
  SG_ CAN_DET_AMPLITUDE : 7|7@0+ (1,-64) [-64|63] "dBsm" IFV_VFP
  SG_ CAN_SCAN_INDEX_2LSB : 17|2@0+ (1,0) [0|3] "" IFV_VFP

BO_ 296 MRR_Detection_009: 8 MRR
  SG_ CAN_DET_CONFID_AZIMUTH : 33|2@0+ (1,0) [0|3] "" IFV_VFP
  SG_ CAN_DET_SUPER_RES_TARGET : 56|1@0+ (1,0) [0|1] "" IFV_VFP
  SG_ CAN_DET_ND_TARGET : 48|1@0+ (1,0) [0|1] "" IFV_VFP
  SG_ CAN_DET_HOST_VEH_CLUTTER : 49|1@0+ (1,0) [0|1] "" IFV_VFP
  SG_ CAN_DET_VALID_LEVEL : 0|1@0+ (1,0) [0|1] "" IFV_VFP
  SG_ CAN_DET_AZIMUTH : 47|14@0+ (0.0003834,-3.1416) [-3.1416|3.13964] "rad" IFV_VFP
  SG_ CAN_DET_RANGE : 31|14@0+ (0.015625,0) [0|255.984] "m" IFV_VFP
  SG_ CAN_DET_RANGE_RATE : 15|14@0+ (0.015625,-128) [-128|127.984] "m/s" IFV_VFP
  SG_ CAN_DET_AMPLITUDE : 7|7@0+ (1,-64) [-64|63] "dBsm" IFV_VFP
  SG_ CAN_SCAN_INDEX_2LSB : 17|2@0+ (1,0) [0|3] "" IFV_VFP

BO_ 295 MRR_Detection_008: 8 MRR
  SG_ CAN_DET_CONFID_AZIMUTH : 33|2@0+ (1,0) [0|3] "" IFV_VFP
  SG_ CAN_DET_SUPER_RES_TARGET : 56|1@0+ (1,0) [0|1] "" IFV_VFP
  SG_ CAN_DET_ND_TARGET : 48|1@0+ (1,0) [0|1] "" IFV_VFP
  SG_ CAN_DET_HOST_VEH_CLUTTER : 49|1@0+ (1,0) [0|1] "" IFV_VFP
  SG_ CAN_DET_VALID_LEVEL : 0|1@0+ (1,0) [0|1] "" IFV_VFP
  SG_ CAN_DET_AZIMUTH : 47|14@0+ (0.0003834,-3.1416) [-3.1416|3.13964] "rad" IFV_VFP
  SG_ CAN_DET_RANGE : 31|14@0+ (0.015625,0) [0|255.984] "m" IFV_VFP
  SG_ CAN_DET_RANGE_RATE : 15|14@0+ (0.015625,-128) [-128|127.984] "m/s" IFV_VFP
  SG_ CAN_DET_AMPLITUDE : 7|7@0+ (1,-64) [-64|63] "dBsm" IFV_VFP
  SG_ CAN_SCAN_INDEX_2LSB : 17|2@0+ (1,0) [0|3] "" IFV_VFP

BO_ 294 MRR_Detection_007: 8 MRR
  SG_ CAN_DET_CONFID_AZIMUTH : 33|2@0+ (1,0) [0|3] "" IFV_VFP
  SG_ CAN_DET_SUPER_RES_TARGET : 56|1@0+ (1,0) [0|1] "" IFV_VFP
  SG_ CAN_DET_ND_TARGET : 48|1@0+ (1,0) [0|1] "" IFV_VFP
  SG_ CAN_DET_HOST_VEH_CLUTTER : 49|1@0+ (1,0) [0|1] "" IFV_VFP
  SG_ CAN_DET_VALID_LEVEL : 0|1@0+ (1,0) [0|1] "" IFV_VFP
  SG_ CAN_DET_AZIMUTH : 47|14@0+ (0.0003834,-3.1416) [-3.1416|3.13964] "rad" IFV_VFP
  SG_ CAN_DET_RANGE : 31|14@0+ (0.015625,0) [0|255.984] "m" IFV_VFP
  SG_ CAN_DET_RANGE_RATE : 15|14@0+ (0.015625,-128) [-128|127.984] "m/s" IFV_VFP
  SG_ CAN_DET_AMPLITUDE : 7|7@0+ (1,-64) [-64|63] "dBsm" IFV_VFP
  SG_ CAN_SCAN_INDEX_2LSB : 17|2@0+ (1,0) [0|3] "" IFV_VFP

BO_ 293 MRR_Detection_006: 8 MRR
  SG_ CAN_DET_CONFID_AZIMUTH : 33|2@0+ (1,0) [0|3] "" IFV_VFP
  SG_ CAN_DET_SUPER_RES_TARGET : 56|1@0+ (1,0) [0|1] "" IFV_VFP
  SG_ CAN_DET_ND_TARGET : 48|1@0+ (1,0) [0|1] "" IFV_VFP
  SG_ CAN_DET_HOST_VEH_CLUTTER : 49|1@0+ (1,0) [0|1] "" IFV_VFP
  SG_ CAN_DET_VALID_LEVEL : 0|1@0+ (1,0) [0|1] "" IFV_VFP
  SG_ CAN_DET_AZIMUTH : 47|14@0+ (0.0003834,-3.1416) [-3.1416|3.13964] "rad" IFV_VFP
  SG_ CAN_DET_RANGE : 31|14@0+ (0.015625,0) [0|255.984] "m" IFV_VFP
  SG_ CAN_DET_RANGE_RATE : 15|14@0+ (0.015625,-128) [-128|127.984] "m/s" IFV_VFP
  SG_ CAN_DET_AMPLITUDE : 7|7@0+ (1,-64) [-64|63] "dBsm" IFV_VFP
  SG_ CAN_SCAN_INDEX_2LSB : 17|2@0+ (1,0) [0|3] "" IFV_VFP

BO_ 292 MRR_Detection_005: 8 MRR
  SG_ CAN_DET_CONFID_AZIMUTH : 33|2@0+ (1,0) [0|3] "" IFV_VFP
  SG_ CAN_DET_SUPER_RES_TARGET : 56|1@0+ (1,0) [0|1] "" IFV_VFP
  SG_ CAN_DET_ND_TARGET : 48|1@0+ (1,0) [0|1] "" IFV_VFP
  SG_ CAN_DET_HOST_VEH_CLUTTER : 49|1@0+ (1,0) [0|1] "" IFV_VFP
  SG_ CAN_DET_VALID_LEVEL : 0|1@0+ (1,0) [0|1] "" IFV_VFP
  SG_ CAN_DET_AZIMUTH : 47|14@0+ (0.0003834,-3.1416) [-3.1416|3.13964] "rad" IFV_VFP
  SG_ CAN_DET_RANGE : 31|14@0+ (0.015625,0) [0|255.984] "m" IFV_VFP
  SG_ CAN_DET_RANGE_RATE : 15|14@0+ (0.015625,-128) [-128|127.984] "m/s" IFV_VFP
  SG_ CAN_DET_AMPLITUDE : 7|7@0+ (1,-64) [-64|63] "dBsm" IFV_VFP
  SG_ CAN_SCAN_INDEX_2LSB : 17|2@0+ (1,0) [0|3] "" IFV_VFP

BO_ 290 MRR_Detection_003: 8 MRR
  SG_ CAN_DET_CONFID_AZIMUTH : 33|2@0+ (1,0) [0|3] "" IFV_VFP
  SG_ CAN_DET_SUPER_RES_TARGET : 56|1@0+ (1,0) [0|1] "" IFV_VFP
  SG_ CAN_DET_ND_TARGET : 48|1@0+ (1,0) [0|1] "" IFV_VFP
  SG_ CAN_DET_HOST_VEH_CLUTTER : 49|1@0+ (1,0) [0|1] "" IFV_VFP
  SG_ CAN_DET_VALID_LEVEL : 0|1@0+ (1,0) [0|1] "" IFV_VFP
  SG_ CAN_DET_AZIMUTH : 47|14@0+ (0.0003834,-3.1416) [-3.1416|3.13964] "rad" IFV_VFP
  SG_ CAN_DET_RANGE : 31|14@0+ (0.015625,0) [0|255.984] "m" IFV_VFP
  SG_ CAN_DET_RANGE_RATE : 15|14@0+ (0.015625,-128) [-128|127.984] "m/s" IFV_VFP
  SG_ CAN_DET_AMPLITUDE : 7|7@0+ (1,-64) [-64|63] "dBsm" IFV_VFP
  SG_ CAN_SCAN_INDEX_2LSB : 17|2@0+ (1,0) [0|3] "" IFV_VFP

BO_ 289 MRR_Detection_002: 8 MRR
  SG_ CAN_DET_CONFID_AZIMUTH : 33|2@0+ (1,0) [0|3] "" IFV_VFP
  SG_ CAN_DET_SUPER_RES_TARGET : 56|1@0+ (1,0) [0|1] "" IFV_VFP
  SG_ CAN_DET_ND_TARGET : 48|1@0+ (1,0) [0|1] "" IFV_VFP
  SG_ CAN_DET_HOST_VEH_CLUTTER : 49|1@0+ (1,0) [0|1] "" IFV_VFP
  SG_ CAN_DET_VALID_LEVEL : 0|1@0+ (1,0) [0|1] "" IFV_VFP
  SG_ CAN_DET_AZIMUTH : 47|14@0+ (0.0003834,-3.1416) [-3.1416|3.13964] "rad" IFV_VFP
  SG_ CAN_DET_RANGE : 31|14@0+ (0.015625,0) [0|255.984] "m" IFV_VFP
  SG_ CAN_DET_RANGE_RATE : 15|14@0+ (0.015625,-128) [-128|127.984] "m/s" IFV_VFP
  SG_ CAN_DET_AMPLITUDE : 7|7@0+ (1,-64) [-64|63] "dBsm" IFV_VFP
  SG_ CAN_SCAN_INDEX_2LSB : 17|2@0+ (1,0) [0|3] "" IFV_VFP

BO_ 256 MRR_Status_CANVersion: 8 MRR
   SG_ CAN_USC_SECTION_COMPATIBILITY : 23|16@0+ (1,0) [0|65535] "" External_Tool
   SG_ CAN_PCAN_MINOR_MRR : 7|8@0+ (1,0) [0|255] "" IFV_VFP
   SG_ CAN_PCAN_MAJOR_MRR : 15|8@0+ (1,0) [0|255] "" IFV_VFP

BO_ 257 MRR_Status_Radar: 8 MRR
   SG_ CAN_INTERFERENCE_TYPE : 11|2@0+ (1,0) [0|3] "" IFV_Host
   SG_ CAN_RECOMMEND_UNCONVERGE : 9|1@0+ (1,0) [0|1] "" IFV_Host
   SG_ CAN_BLOCKAGE_SIDELOBE_FILTER_VAL : 15|4@0+ (1,0) [0|15] "" IFV_Host
   SG_ CAN_RADAR_ALIGN_INCOMPLETE : 8|1@0+ (1,0) [0|1] "" IFV_VFP
   SG_ CAN_BLOCKAGE_SIDELOBE : 4|1@0+ (1,0) [0|1] "" IFV_VFP
   SG_ CAN_BLOCKAGE_MNR : 5|1@0+ (1,0) [0|1] "" IFV_VFP
   SG_ CAN_RADAR_EXT_COND_NOK : 1|1@0+ (1,0) [0|1] "" IFV_VFP
   SG_ CAN_RADAR_ALIGN_OUT_RANGE : 2|1@0+ (1,0) [0|1] "" IFV_VFP
   SG_ CAN_RADAR_ALIGN_NOT_START : 0|1@0+ (1,0) [0|1] "" IFV_VFP
   SG_ CAN_RADAR_OVERHEAT_ERROR : 3|1@0+ (1,0) [0|1] "" IFV_VFP
   SG_ CAN_RADAR_NOT_OP : 6|1@0+ (1,0) [0|1] "" IFV_VFP
   SG_ CAN_XCVR_OPERATIONAL : 7|1@0+ (1,0) [0|1] "" IFV_VFP

BO_ 288 MRR_Detection_001: 8 MRR
  SG_ CAN_DET_CONFID_AZIMUTH : 33|2@0+ (1,0) [0|3] "" IFV_VFP
  SG_ CAN_DET_SUPER_RES_TARGET : 56|1@0+ (1,0) [0|1] "" IFV_VFP
  SG_ CAN_DET_ND_TARGET : 48|1@0+ (1,0) [0|1] "" IFV_VFP
  SG_ CAN_DET_HOST_VEH_CLUTTER : 49|1@0+ (1,0) [0|1] "" IFV_VFP
  SG_ CAN_DET_VALID_LEVEL : 0|1@0+ (1,0) [0|1] "" IFV_VFP
  SG_ CAN_DET_AZIMUTH : 47|14@0+ (0.0003834,-3.1416) [-3.1416|3.13964] "rad" IFV_VFP
  SG_ CAN_DET_RANGE : 31|14@0+ (0.015625,0) [0|255.984] "m" IFV_VFP
  SG_ CAN_DET_RANGE_RATE : 15|14@0+ (0.015625,-128) [-128|127.984] "m/s" IFV_VFP
  SG_ CAN_DET_AMPLITUDE : 7|7@0+ (1,-64) [-64|63] "dBsm" IFV_VFP
  SG_ CAN_SCAN_INDEX_2LSB : 17|2@0+ (1,0) [0|3] "" IFV_VFP

VAL_ 34 IPMA_PCAN_DataRangeCheck 1 "Fault Present" 0 "No Fault";
VAL_ 34 IPMA_PCAN_MissingMsg 1 "Fault Present" 0 "No Fault ";
VAL_ 34 VINSignalCompareFailure 1 "Fault Present" 0 "No Fault";
VAL_ 34 ModuleNotConfiguredError 1 "Fault Present" 0 "No Fault";
VAL_ 34 CarCfgNotConfiguredError 1 "Fault Present" 0 "No Fault";
VAL_ 33 Active_Flt_Latched_byte7_bit7 1 "Fault Present" 0 "No Fault";
VAL_ 33 Active_Flt_Latched_byte7_bit6 1 "Fault Present" 0 "No Fault";
VAL_ 33 Active_Flt_Latched_byte7_bit5 1 "Fault Present" 0 "No Fault";
VAL_ 33 Active_Flt_Latched_byte7_bit4 1 "Fault Present" 0 "No Fault";
VAL_ 33 ARMtoDSPChksumFault 1 "Fault Present" 0 "No Fault";
VAL_ 33 DSPtoArmChksumFault 1 "Fault Present" 0 "No Fault";
VAL_ 33 HostToArmChksumFault 1 "Fault Present" 0 "No Fault";
VAL_ 33 ARMtoHostChksumFault 1 "Fault Present" 0 "No Fault";
VAL_ 33 LoopBWOutOfRange 1 "Fault Present" 0 "No Fault";
VAL_ 33 DSPOverrunFault 1 "Fault Present" 0 "No Fault";
VAL_ 33 Active_Flt_Latched_byte6_bit5 1 "Fault Present" 0 "No Fault";
VAL_ 33 TuningSensitivityFault 1 "Fault Present" 0 "No Fault";
VAL_ 33 SaturatedTuningFreqFault 1 "Fault Present" 0 "No Fault";
VAL_ 33 LocalOscPowerFault 1 "Fault Present" 0 "No Fault";
VAL_ 33 TransmitterPowerFault 1 "Fault Present" 0 "No Fault";
VAL_ 33 Active_Flt_Latched_byte6_bit0 1 "Fault Present" 0 "No Fault";
VAL_ 33 Active_Flt_Latched_byte5_bit7 1 "Fault Present" 0 "No Fault";
VAL_ 33 Active_Flt_Latched_byte5_bit6 1 "Fault Present" 0 "No Fault";
VAL_ 33 XCVRDeviceSPIFault 1 "Fault Present" 0 "No Fault";
VAL_ 33 FreqSynthesizerSPIFault 1 "Fault Present" 0 "No Fault";
VAL_ 33 AnalogConverterDevicSPIFault 1 "Fault Present" 0 "No Fault";
VAL_ 33 SidelobeBlockage 1 "Fault Present" 0 "No Fault";
VAL_ 33 Active_Flt_Latched_byte5_bit1 1 "Fault Present" 0 "No Fault";
VAL_ 33 MNRBlocked 1 "Fault Present" 0 "No Fault";
VAL_ 33 ECUTempHighFault 1 "Fault Present" 0 "No Fault";
VAL_ 33 TransmitterTempHighFault 1 "Fault Present" 0 "No Fault";
VAL_ 33 AlignmentRoutineFailedFault 1 "Fault Present" 0 "No Fault";
VAL_ 33 UnreasonableRadarData 1 "Fault Present" 0 "No Fault";
VAL_ 33 MicroprocessorTempHighFault 1 "Fault Present" 0 "No Fault";
VAL_ 33 VerticalAlignmentOutOfRange 1 "Fault Present" 0 "No Fault";
VAL_ 33 HorizontalAlignmentOutOfRange 1 "Fault Present" 0 "No Fault";
VAL_ 33 FactoryAlignmentMode 1 "Fault Present" 0 "No Fault";
VAL_ 33 BatteryLowFault 1 "Fault Present" 0 "No Fault";
VAL_ 33 BatteryHighFault 1 "Fault Present" 0 "No Fault";
VAL_ 33 v_1p25SupplyOutOfRange 1 "Fault Present" 0 "No Fault";
VAL_ 33 Active_Flt_Latched_byte3_bit4 1 "Fault Present" 0 "No Fault";
VAL_ 33 ThermistorOutOfRange 1 "Fault Present" 0 "No Fault";
VAL_ 33 v_3p3DACSupplyOutOfRange 1 "Fault Present" 0 "No Fault";
VAL_ 33 v_3p3RAWSupplyOutOfRange 1 "Fault Present" 0 "No Fault";
VAL_ 33 v_5_SupplyOutOfRange 1 "Fault Present" 0 "No Fault";
VAL_ 33 TransmitterIDFault 1 "Fault Present" 0 "No Fault";
VAL_ 33 Active_Flt_Latched_byte2_bit6 1 "Fault Present" 0 "No Fault";
VAL_ 33 Active_Flt_Latched_byte2_bit5 1 "Fault Present" 0 "No Fault";
VAL_ 33 Active_Flt_Latched_byte2_bit4 1 "Fault Present" 0 "No Fault";
VAL_ 33 Active_Flt_Latched_byte2_bit3 1 "Fault Present" 0 "No Fault";
VAL_ 33 Active_Flt_Latched_byte2_bit2 1 "Fault Present" 0 "No Fault";
VAL_ 33 PCANMissingMsgFault 1 "Fault Present" 0 "No Fault";
VAL_ 33 PCANBusOff 1 "Fault Present" 0 "No Fault";
VAL_ 33 Active_Flt_Latched_byte1_bit7 1 "Fault Present" 0 "No Fault";
VAL_ 33 Active_Flt_Latched_byte1_bit6 1 "Fault Present" 0 "No Fault";
VAL_ 33 InstructionSetCheckFault 1 "Fault Present" 0 "No Fault";
VAL_ 33 StackOverflowFault 1 "Fault Present" 0 "No Fault";
VAL_ 33 WatchdogFault 1 "Fault Present" 0 "No Fault";
VAL_ 33 PLLLockFault 1 "Fault Present" 0 "No Fault";
VAL_ 33 Active_Flt_Latched_byte1_bit1 1 "Fault Present" 0 "No Fault";
VAL_ 33 RAMMemoryTestFault 1 "Fault Present" 0 "No Fault";
VAL_ 33 USCValidationFault 1 "Fault Present" 0 "No Fault";
VAL_ 33 Active_Flt_Latched_byte0_bit6 1 "Fault Present" 0 "No Fault";
VAL_ 33 Active_Flt_Latched_byte0_bit5 1 "Fault Present" 0 "No Fault";
VAL_ 33 Active_Flt_Latched_byte0_bit4 1 "Fault Present" 0 "No Fault";
VAL_ 33 Active_Flt_Latched_byte0_bit3 1 "Fault Present" 0 "No Fault";
VAL_ 33 KeepAliveChecksumFault 1 "Fault Present" 0 "No Fault";
VAL_ 33 ProgramCalibrationFlashChecksum 1 "Fault Present" 0 "No Fault";
VAL_ 33 ApplicationFlashChecksumFault 1 "Fault Present" 0 "No Fault";
VAL_ 371 CAN_AUTO_ALIGN_HANGLE_QF 3 "Accurate" 2 "Innacurate" 1 "Temporarily undefined" 0 "Undefined";
VAL_ 371 CAN_ALIGNMENT_STATUS 15 "Undefined_2" 14 "Undefined_1" 13 "Low Amplitude (Flat-plate only)" 12 "No Peak (Flat-plate only)" 11 "Fail Ver and Hor OutOfRange" 10 "Fail Vertical Align OutOfRange" 9 "Fail Horizontal Align OutOfRange" 8 "Fail Time Out" 7 "Fail Only Right Target Found" 6 "Fail Only Left Target Found" 5 "Fail Variance Too Large" 4 "Fail Deviation Too Large" 3 "Fail No Target" 2 "Success" 1 "Busy" 0 "Off";
VAL_ 371 CAN_ALIGNMENT_STATE 6 "Static alignment flat-plate" 5 "Static alignment 2-target" 4 "Static alignment 1-target" 3 "Service alignment" 2 "Short track alignment" 1 "Auto alignment" 0 "Off";
VAL_ 291 CAN_DET_CONFID_AZIMUTH 3 "Low" 2 "Medium_Low" 1 "Medium_High" 0 "High";
VAL_ 351 CAN_DET_CONFID_AZIMUTH 3 "Low" 2 "Medium_Low" 1 "Medium_High" 0 "High";
VAL_ 350 CAN_DET_CONFID_AZIMUTH 3 "Low" 2 "Medium_Low" 1 "Medium_High" 0 "High";
VAL_ 349 CAN_DET_CONFID_AZIMUTH 3 "Low" 2 "Medium_Low" 1 "Medium_High" 0 "High";
VAL_ 348 CAN_DET_CONFID_AZIMUTH 3 "Low" 2 "Medium_Low" 1 "Medium_High" 0 "High";
VAL_ 347 CAN_DET_CONFID_AZIMUTH 3 "Low" 2 "Medium_Low" 1 "Medium_High" 0 "High";
VAL_ 346 CAN_DET_CONFID_AZIMUTH 3 "Low" 2 "Medium_Low" 1 "Medium_High" 0 "High";
VAL_ 345 CAN_DET_CONFID_AZIMUTH 3 "Low" 2 "Medium_Low" 1 "Medium_High" 0 "High";
VAL_ 344 CAN_DET_CONFID_AZIMUTH 3 "Low" 2 "Medium_Low" 1 "Medium_High" 0 "High";
VAL_ 343 CAN_DET_CONFID_AZIMUTH 3 "Low" 2 "Medium_Low" 1 "Medium_High" 0 "High";
VAL_ 342 CAN_DET_CONFID_AZIMUTH 3 "Low" 2 "Medium_Low" 1 "Medium_High" 0 "High";
VAL_ 335 CAN_DET_CONFID_AZIMUTH 3 "Low" 2 "Medium_Low" 1 "Medium_High" 0 "High";
VAL_ 334 CAN_DET_CONFID_AZIMUTH 3 "Low" 2 "Medium_Low" 1 "Medium_High" 0 "High";
VAL_ 333 CAN_DET_CONFID_AZIMUTH 3 "Low" 2 "Medium_Low" 1 "Medium_High" 0 "High";
VAL_ 332 CAN_DET_CONFID_AZIMUTH 3 "Low" 2 "Medium_Low" 1 "Medium_High" 0 "High";
VAL_ 331 CAN_DET_CONFID_AZIMUTH 3 "Low" 2 "Medium_Low" 1 "Medium_High" 0 "High";
VAL_ 330 CAN_DET_CONFID_AZIMUTH 3 "Low" 2 "Medium_Low" 1 "Medium_High" 0 "High";
VAL_ 329 CAN_DET_CONFID_AZIMUTH 3 "Low" 2 "Medium_Low" 1 "Medium_High" 0 "High";
VAL_ 328 CAN_DET_CONFID_AZIMUTH 3 "Low" 2 "Medium_Low" 1 "Medium_High" 0 "High";
VAL_ 327 CAN_DET_CONFID_AZIMUTH 3 "Low" 2 "Medium_Low" 1 "Medium_High" 0 "High";
VAL_ 325 CAN_DET_CONFID_AZIMUTH 3 "Low" 2 "Medium_Low" 1 "Medium_High" 0 "High";
VAL_ 324 CAN_DET_CONFID_AZIMUTH 3 "Low" 2 "Medium_Low" 1 "Medium_High" 0 "High";
VAL_ 323 CAN_DET_CONFID_AZIMUTH 3 "Low" 2 "Medium_Low" 1 "Medium_High" 0 "High";
VAL_ 322 CAN_DET_CONFID_AZIMUTH 3 "Low" 2 "Medium_Low" 1 "Medium_High" 0 "High";
VAL_ 321 CAN_DET_CONFID_AZIMUTH 3 "Low" 2 "Medium_Low" 1 "Medium_High" 0 "High";
VAL_ 320 CAN_DET_CONFID_AZIMUTH 3 "Low" 2 "Medium_Low" 1 "Medium_High" 0 "High";
VAL_ 319 CAN_DET_CONFID_AZIMUTH 3 "Low" 2 "Medium_Low" 1 "Medium_High" 0 "High";
VAL_ 318 CAN_DET_CONFID_AZIMUTH 3 "Low" 2 "Medium_Low" 1 "Medium_High" 0 "High";
VAL_ 317 CAN_DET_CONFID_AZIMUTH 3 "Low" 2 "Medium_Low" 1 "Medium_High" 0 "High";
VAL_ 316 CAN_DET_CONFID_AZIMUTH 3 "Low" 2 "Medium_Low" 1 "Medium_High" 0 "High";
VAL_ 314 CAN_DET_CONFID_AZIMUTH 3 "Low" 2 "Medium_Low" 1 "Medium_High" 0 "High";
VAL_ 313 CAN_DET_CONFID_AZIMUTH 3 "Low" 2 "Medium_Low" 1 "Medium_High" 0 "High";
VAL_ 312 CAN_DET_CONFID_AZIMUTH 3 "Low" 2 "Medium_Low" 1 "Medium_High" 0 "High";
VAL_ 311 CAN_DET_CONFID_AZIMUTH 3 "Low" 2 "Medium_Low" 1 "Medium_High" 0 "High";
VAL_ 310 CAN_DET_CONFID_AZIMUTH 3 "Low" 2 "Medium_Low" 1 "Medium_High" 0 "High";
VAL_ 309 CAN_DET_CONFID_AZIMUTH 3 "Low" 2 "Medium_Low" 1 "Medium_High" 0 "High";
VAL_ 308 CAN_DET_CONFID_AZIMUTH 3 "Low" 2 "Medium_Low" 1 "Medium_High" 0 "High";
VAL_ 307 CAN_DET_CONFID_AZIMUTH 3 "Low" 2 "Medium_Low" 1 "Medium_High" 0 "High";
VAL_ 306 CAN_DET_CONFID_AZIMUTH 3 "Low" 2 "Medium_Low" 1 "Medium_High" 0 "High";
VAL_ 305 CAN_DET_CONFID_AZIMUTH 3 "Low" 2 "Medium_Low" 1 "Medium_High" 0 "High";
VAL_ 341 CAN_DET_CONFID_AZIMUTH 3 "Low" 2 "Medium_Low" 1 "Medium_High" 0 "High";
VAL_ 340 CAN_DET_CONFID_AZIMUTH 3 "Low" 2 "Medium_Low" 1 "Medium_High" 0 "High";
VAL_ 339 CAN_DET_CONFID_AZIMUTH 3 "Low" 2 "Medium_Low" 1 "Medium_High" 0 "High";
VAL_ 338 CAN_DET_CONFID_AZIMUTH 3 "Low" 2 "Medium_Low" 1 "Medium_High" 0 "High";
VAL_ 337 CAN_DET_CONFID_AZIMUTH 3 "Low" 2 "Medium_Low" 1 "Medium_High" 0 "High";
VAL_ 336 CAN_DET_CONFID_AZIMUTH 3 "Low" 2 "Medium_Low" 1 "Medium_High" 0 "High";
VAL_ 326 CAN_DET_CONFID_AZIMUTH 3 "Low" 2 "Medium_Low" 1 "Medium_High" 0 "High";
VAL_ 315 CAN_DET_CONFID_AZIMUTH 3 "Low" 2 "Medium_Low" 1 "Medium_High" 0 "High";
VAL_ 304 CAN_DET_CONFID_AZIMUTH 3 "Low" 2 "Medium_Low" 1 "Medium_High" 0 "High";
VAL_ 303 CAN_DET_CONFID_AZIMUTH 3 "Low" 2 "Medium_Low" 1 "Medium_High" 0 "High";
VAL_ 302 CAN_DET_CONFID_AZIMUTH 3 "Low" 2 "Medium_Low" 1 "Medium_High" 0 "High";
VAL_ 301 CAN_DET_CONFID_AZIMUTH 3 "Low" 2 "Medium_Low" 1 "Medium_High" 0 "High";
VAL_ 300 CAN_DET_CONFID_AZIMUTH 3 "Low" 2 "Medium_Low" 1 "Medium_High" 0 "High";
VAL_ 299 CAN_DET_CONFID_AZIMUTH 3 "Low" 2 "Medium_Low" 1 "Medium_High" 0 "High";
VAL_ 298 CAN_DET_CONFID_AZIMUTH 3 "Low" 2 "Medium_Low" 1 "Medium_High" 0 "High";
VAL_ 297 CAN_DET_CONFID_AZIMUTH 3 "Low" 2 "Medium_Low" 1 "Medium_High" 0 "High";
VAL_ 296 CAN_DET_CONFID_AZIMUTH 3 "Low" 2 "Medium_Low" 1 "Medium_High" 0 "High";
VAL_ 295 CAN_DET_CONFID_AZIMUTH 3 "Low" 2 "Medium_Low" 1 "Medium_High" 0 "High";
VAL_ 294 CAN_DET_CONFID_AZIMUTH 3 "Low" 2 "Medium_Low" 1 "Medium_High" 0 "High";
VAL_ 293 CAN_DET_CONFID_AZIMUTH 3 "Low" 2 "Medium_Low" 1 "Medium_High" 0 "High";
VAL_ 292 CAN_DET_CONFID_AZIMUTH 3 "Low" 2 "Medium_Low" 1 "Medium_High" 0 "High";
VAL_ 290 CAN_DET_CONFID_AZIMUTH 3 "Low" 2 "Medium_Low" 1 "Medium_High" 0 "High";
VAL_ 289 CAN_DET_CONFID_AZIMUTH 3 "Low" 2 "Medium_Low" 1 "Medium_High" 0 "High";
VAL_ 257 CAN_INTERFERENCE_TYPE 2 "Star PD-Like" 1 "Slow FMCW" 0 "No Interference";
VAL_ 257 CAN_RECOMMEND_UNCONVERGE 1 "Recommended" 0 "Not Recommended";
VAL_ 257 CAN_RADAR_ALIGN_INCOMPLETE 1 "Alignment Incomplete" 0 "Alignment Completed";
VAL_ 257 CAN_BLOCKAGE_SIDELOBE 1 "Radar Blockage" 0 "No Radar Blockage";
VAL_ 257 CAN_BLOCKAGE_MNR 1 "Radar Blockage" 0 "No Radar Blockage";
VAL_ 257 CAN_RADAR_EXT_COND_NOK 1 "Too high temp or insufficient pw" 0 "External conditions OK";
VAL_ 257 CAN_RADAR_ALIGN_OUT_RANGE 1 "Radar out of range" 0 "Radar within range";
VAL_ 257 CAN_RADAR_ALIGN_NOT_START 1 "Radar align not started" 0 "Radar align started";
VAL_ 257 CAN_RADAR_OVERHEAT_ERROR 1 "Radar overheat condition" 0 "No Overheat";
VAL_ 257 CAN_RADAR_NOT_OP 1 "Radar not operational" 0 "Radar operational";
VAL_ 257 CAN_XCVR_OPERATIONAL 1 "On" 0 "Off ";
VAL_ 288 CAN_DET_CONFID_AZIMUTH 3 "Low" 2 "Medium_Low" 1 "Medium_High" 0 "High";
